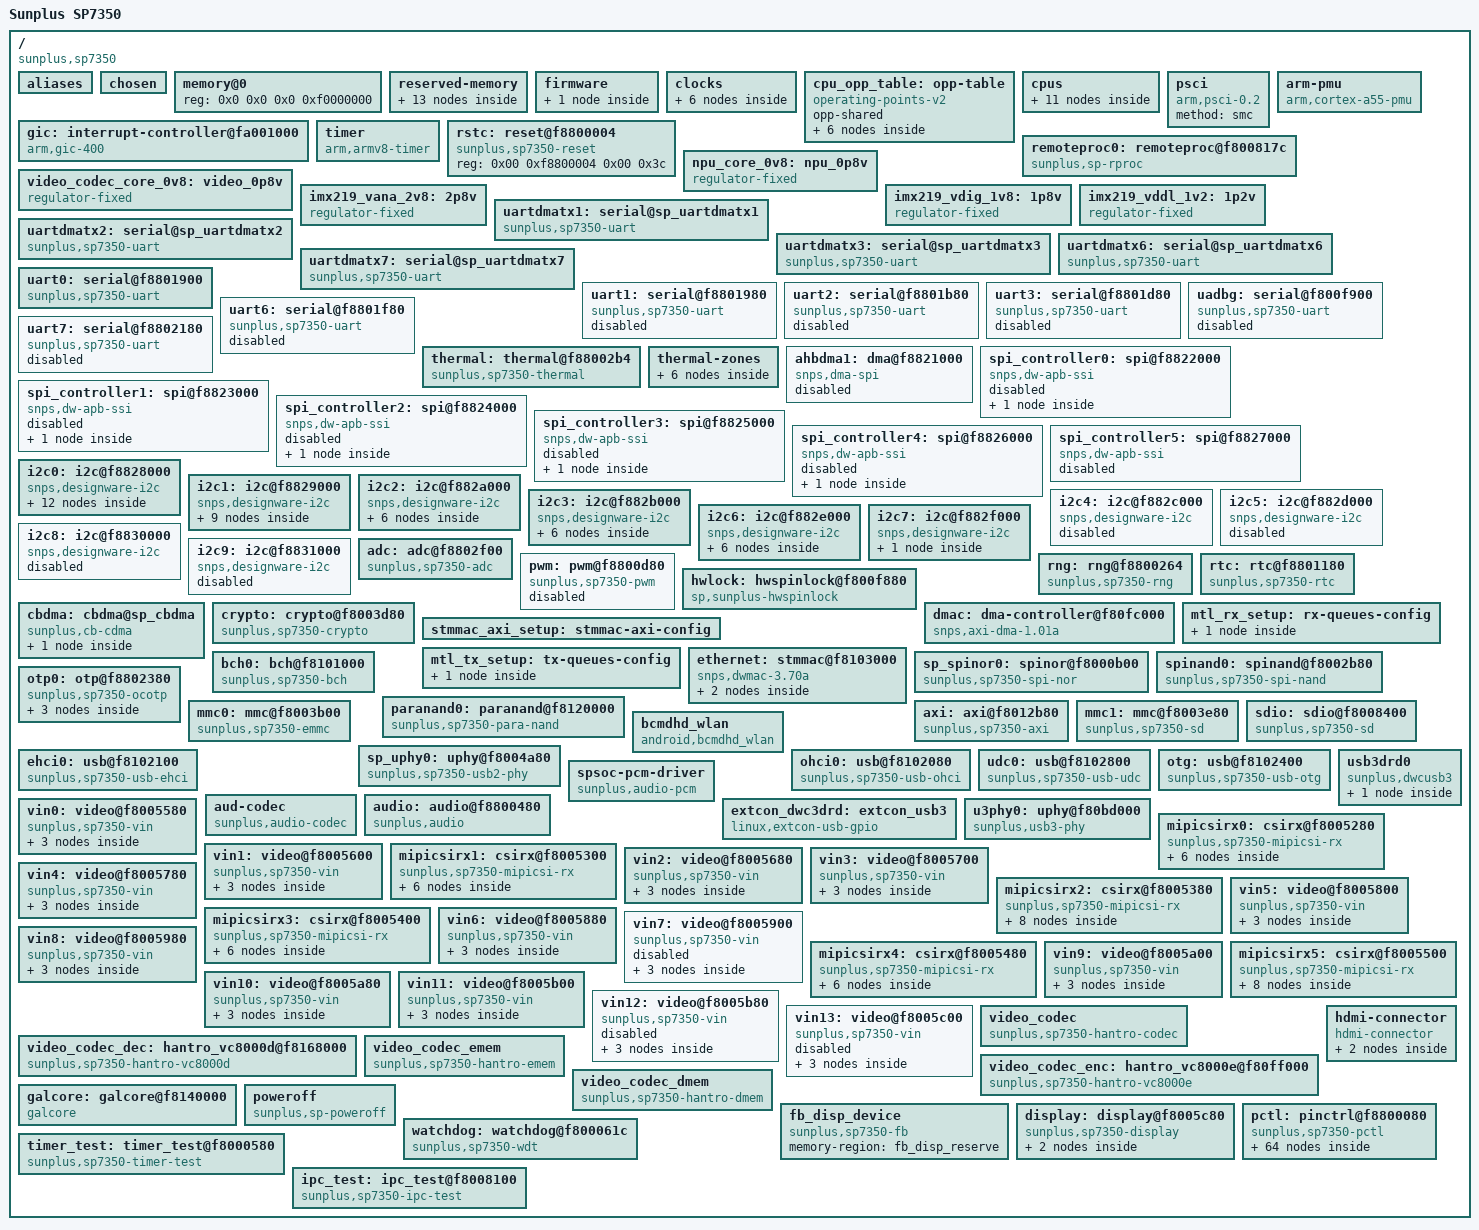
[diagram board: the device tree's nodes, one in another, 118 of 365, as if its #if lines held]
// SPDX-License-Identifier: (GPL-2.0 OR MIT)
/* Copyright (c) 2018-2019 Sunplus */

/dts-v1/;

#define CONFIG_SOC_SP7350

#include <dt-bindings/interrupt-controller/irq.h>
#include <dt-bindings/interrupt-controller/arm-gic.h>
#include <dt-bindings/gpio/gpio.h>
#include <dt-bindings/clock/sp-sp7350.h>
#include <dt-bindings/reset/sp-sp7350.h>
#include <dt-bindings/pinctrl/sppctl-sp7350.h>

//#define ENABLE_DMATX1
//#define ENABLE_DMATX2
//#define ENABLE_DMATX3
//#define ENABLE_DMATX6
//#define ENABLE_DMATX7

//#define MIPI_CSI_4VC
//#define IMX219_IN0
//#define IMX219_IN1
//#define IMX219_IN2
//#define IMX219_IN3
//#define IMX219_IN4
//#define IMX219_IN5
//#define TP2815_IN0
//#define TP2815_IN0_1LANE
//#define TP2815_IN0_2VC
//#define TP2815_IN1
//#define TP2815_IN1_1LANE
//#define TP2815_IN1_2VC
//#define TP2815_IN2
//#define TP2815_IN2_1LANE
//#define TP2815_IN2_2LANES
//#define TP2815_IN2_2VC
//#define TP2815_IN4
//#define TP2815_IN4_1LANE
//#define TP2815_IN4_2VC
//#define TP2815_IN5
//#define TP2815_IN5_1LANE
//#define TP2815_IN5_2LANES
//#define TP2815_IN5_2VC
//#define TP2815_IN5_4VC

//#define AP6256_WIFI
//#define AP6256_BT

//#define DISP_MIPITX_CSI
//#define DISP_MIPITX_CSI_480P
//#define DISP_MIPITX_CSI_720P
//#define DISP_MIPITX_CSI_1080P
//#define DISP_MIPITX_CSI_3840

//#define DISP_MIPITX_DSI_PANEL_240X320

//#define DISP_MIPITX_DSI_PANEL_480X1280
//#define DISP_MIPITX_DSI_VPP_SRC_480P
//#define DISP_MIPITX_DSI_VPP_SRC_720P
//#define DISP_MIPITX_DSI_VPP_SRC_1080P
//#define DISP_MIPITX_DSI_VPP_SRC_3840

#define LT8912B_HDMI_ENABLE
//#define LT8912B_HDMI_480P
//#define LT8912B_HDMI_720P
#define LT8912B_HDMI_1080P

/ {
	model = "Sunplus SP7350";
	compatible = "sunplus,sp7350";
	interrupt-parent = <&gic>;
	#address-cells = <2>;
	#size-cells = <2>;

	aliases {
#ifdef ENABLE_DMATX1
		serial21 = &uartdmatx1;
#endif
#ifdef ENABLE_DMATX2
		serial22 = &uartdmatx2;
#endif
#ifdef ENABLE_DMATX3
		serial23 = &uartdmatx3;
#endif
#ifdef ENABLE_DMATX6
		serial26 = &uartdmatx6;
#endif
#ifdef ENABLE_DMATX7
		serial27 = &uartdmatx7;
#endif
		serial0 = &uart0;
		serial1 = &uart1;
		serial2 = &uart2;
		serial3 = &uart3;
		serial5 = &uadbg;
		serial6 = &uart6;
		serial7 = &uart7;

		spim0 = &spi_controller0;
		spim1 = &spi_controller1;
		spim2 = &spi_controller2;
		spim3 = &spi_controller3;
		spim4 = &spi_controller4;
		spis5 = &spi_controller5;

		spi0 = &sp_spinor0;

		usb-device0 = &udc0;
	};

	chosen {
		bootargs = "console=ttyS0,115200 earlycon loglevel=8 no_console_suspend ";
		stdout-path = "serial0:115200n8";
	};

	memory@0 {
		device_type = "memory";
		reg = <0x0 0x0        0x0 0xf0000000>;
	};

	reserved-memory {
		#address-cells = <2>;
		#size-cells = <2>;
		ranges;

		/* TF-A reserve memory: 0x200000-0x2fffff, total 1M */
		tfa_reserve@200000 {
			reg = <0x0 0x200000 0x0 0x100000>;
			no-map;
		};

		/*OP-TEE reserve memory: 0x300000-0x4fffff, total 2M */
		optee_reserve@300000 {
			reg = <0x0 0x300000 0x0 0x200000>;
			no-map;
		};

		/* warmboot reserve memory: 0x100000-0x200000, total 1M, load firmware in rproc */
		rproc_0_reserved: rproc0@100000 {
			compatible = "shared-dma-pool";
			reg = <0x0 0x100000 0x0 0x100000>;
			no-map;
		};

		/* mipi-csi rx reserve memory: 0x4f600000~0x5bdfffff, total 200M */
		mipicsirx_reserve: mipicsirx@4f600000 {
			compatible = "shared-dma-pool";
			reg = <0x0 0x4f600000 0x0 0x0c800000>;
			no-map;
		};

		/* remoteproc reserve memory: 0x5be00000-0x5befffff, total 1M */
		vdev0buffer: vdev0buffer@5be00000 {
			compatible = "shared-dma-pool";
			reg = <0x0 0x5be00000 0x0 0x100000>;
			no-map;
		};
		vdev0vring0: vdev0vring0@5bf00000 {
			compatible = "shared-dma-pool";
			reg = <0x0 0x5bf00000 0x0 0x4000>;
			no-map;
		};
		vdev0vring1: vdev0vring1@5bf04000 {
			compatible = "shared-dma-pool";
			reg = <0x0 0x5bf04000 0x0 0x4000>;
			no-map;
		};
		vdev0_reserve: vdev0_reserve@5bf08000 {
			compatible = "shared-dma-pool";
			reg = <0x0 0x5bf08000 0x0 0xf8000>;
			no-map;
		};

		/* display fb reserve memory: 0x5c000000 ~ 0x5fffffff, total 64M */
		fb_disp_reserve: fb@5c000000 {
			compatible = "shared-dma-pool";
			reg = <0x0 0x5c000000 0x0 0x4000000>;
			no-map;
		};

		/* video encoder reserve memory: 0x60000000~0x73ffffff, total 320M */
		video_codec_encode: vcodec@60000000 {
			reg = <0x0 0x60000000 0x0 0x14000000>;
			no-map;
		};

		/* video decoder reserve memory: 0x74000000~0x77ffffff, total 64M */
		video_codec_decode: vcodec@74000000 {
			reg = <0x0 0x74000000 0x0 0x04000000>;
			no-map;
		};

		/* NPU reserve memory: 0x780000000 ~ 0x7fffffff, total 128M */
		npu_reserve: npu_reserve@78000000 {
			reg = <0x0 0x78000000 0x0 0x8000000>;
			no-map;
		};

		/* CM4 reserve memory: 0xfa240000 ~ 0xfa29ffff, total 384K */
		rproc0runaddr: cm4runaddr@fa240000 {
			compatible = "shared-dma-pool";
			reg = <0x0 0xfa240000 0x0 0x60000>;
			no-map;
		};
	};

	firmware {
		optee {
			compatible = "linaro,optee-tz";
			method = "smc";
		};
	};

	clocks {
		#address-cells = <2>;
		#size-cells = <2>;
		ranges;

		extclk: osc0 {
			compatible = "fixed-clock";
			#clock-cells = <0>;
			clock-frequency = <XTAL>;
			clock-output-names = "extclk";
		};

		rtcclk: rtcclk {
			compatible = "fixed-clock";
			#clock-cells = <0>;
			clock-frequency = <32000>;
			clock-output-names = "f_32k";
		};

		mipiclk: mipiclk {
			compatible = "fixed-clock";
			#clock-cells = <0>;
			clock-frequency = <320000000>;
			clock-output-names = "f_320m";
		};

		clkc: clkc@f8800104 {
			compatible = "sunplus,sp7350-clkc";
			reg = <0x00 0xf8800104 0x00 0x1fc>,  // MOON G2.1~G6
			      <0x00 0xf8000f00 0x00 0x080>;  // G30 QCTL
			#clock-cells = <1>;
		};

		imx219_clk: camera-imx219-clk {
			compatible = "fixed-clock";
			#clock-cells = <0>;
			clock-frequency = <24000000>;
		};

		tp2815_clk: camera-tp2815-clk {
			compatible = "fixed-clock";
			#clock-cells = <0>;
			clock-frequency = <27000000>;
		};
	};

	cpu_opp_table: opp-table {
		compatible = "operating-points-v2";
		opp-shared;

		opp-5 {
			opp-hz = /bits/ 64 <500000000>;
			opp-microvolt = <670000>;
		};

		opp-10 {
			opp-hz = /bits/ 64 <1000000000>;
			opp-microvolt = <700000>;
		};

		opp-15 {
			opp-hz = /bits/ 64 <1500000000>;
			opp-microvolt = <750000>;
		};

		opp-16 {
			opp-hz = /bits/ 64 <1600000000>;
			opp-microvolt = <770000>;
		};

		opp-17 {
			opp-hz = /bits/ 64 <1700000000>;
			opp-microvolt = <800000>;
		};

		opp-18 {
			opp-hz = /bits/ 64 <1800000000>;
			opp-microvolt = <840000>;
		};

		/*opp-19 {
			opp-hz = /bits/ 64 <1900000000>;
			opp-microvolt = <1000000>;
		};

		opp-20 {
			opp-hz = /bits/ 64 <2000000000>;
			opp-microvolt = <1000000>;
		};

		opp-21 {
			opp-hz = /bits/ 64 <2100000000>;
			opp-microvolt = <1000000>;
		};*/
	};

	cpus {
		#address-cells = <1>;
		#size-cells = <0>;

		cpu0: cpu@0 {
			device_type = "cpu";
			compatible = "arm,cortex-a55";
			reg = <0x0000>;
			enable-method = "psci";
			clocks = <&clkc PLLC>, <&clkc PLLL3>;
			clock-names = "PLLC", "PLLL3";
			proc-supply = <&rt5759_vproc_reg>;
			operating-points-v2 = <&cpu_opp_table>;
			next-level-cache = <&L2_0>;
			cpu-idle-states = <&CPU_SLEEP>;
		};

		cpu1: cpu@1 {
			device_type = "cpu";
			compatible = "arm,cortex-a55";
			reg = <0x0100>;
			enable-method = "psci";
			clocks = <&clkc PLLC>, <&clkc PLLL3>;
			clock-names = "PLLC", "PLLL3";
			proc-supply = <&rt5759_vproc_reg>;
			operating-points-v2 = <&cpu_opp_table>;
			next-level-cache = <&L2_1>;
			cpu-idle-states = <&CPU_SLEEP>;
		};

		cpu2: cpu@2 {
			device_type = "cpu";
			compatible = "arm,cortex-a55";
			reg = <0x0200>;
			enable-method = "psci";
			clocks = <&clkc PLLC>, <&clkc PLLL3>;
			clock-names = "PLLC", "PLLL3";
			proc-supply = <&rt5759_vproc_reg>;
			operating-points-v2 = <&cpu_opp_table>;
			next-level-cache = <&L2_2>;
			cpu-idle-states = <&CPU_SLEEP>;
		};

		cpu3: cpu@3 {
			device_type = "cpu";
			compatible = "arm,cortex-a55";
			reg = <0x0300>;
			enable-method = "psci";
			clocks = <&clkc PLLC>, <&clkc PLLL3>;
			clock-names = "PLLC", "PLLL3";
			proc-supply = <&rt5759_vproc_reg>;
			operating-points-v2 = <&cpu_opp_table>;
			next-level-cache = <&L2_3>;
			cpu-idle-states = <&CPU_SLEEP>;
		};

		idle-states {
			entry-method = "psci";

			CPU_SLEEP: cpu-sleep {
				compatible = "arm,idle-state";
				local-timer-stop;
				arm,psci-suspend-param = <0x0000000>;
				entry-latency-us = <120>;
				exit-latency-us = <250>;
				min-residency-us = <900>;
			};
		};

		L2_0: l2-cache-0 {
			compatible = "cache";
			cache-level = <2>;
			next-level-cache = <&L3>;
		};

		L2_1: l2-cache-1 {
			compatible = "cache";
			cache-level = <2>;
			next-level-cache = <&L3>;
		};

		L2_2: l2-cache-2 {
			compatible = "cache";
			cache-level = <2>;
			next-level-cache = <&L3>;
		};

		L2_3: l2-cache-3 {
			compatible = "cache";
			cache-level = <2>;
			next-level-cache = <&L3>;
		};

		L3: l3-cache {
			compatible = "cache";
			cache-level = <3>;
		};
	};

	psci {
		compatible = "arm,psci-0.2";
		method = "smc";
	};

	arm-pmu {
		compatible = "arm,cortex-a55-pmu", "arm,armv8-pmuv3";
		interrupts = <GIC_SPI 475 IRQ_TYPE_LEVEL_HIGH>,
			     <GIC_SPI 476 IRQ_TYPE_LEVEL_HIGH>,
			     <GIC_SPI 477 IRQ_TYPE_LEVEL_HIGH>,
			     <GIC_SPI 478 IRQ_TYPE_LEVEL_HIGH>;
		interrupt-affinity = <&cpu0>, <&cpu1>, <&cpu2>, <&cpu3>;
	};

	gic: interrupt-controller@fa001000 {
		compatible = "arm,gic-400";
		#interrupt-cells = <3>;
		interrupt-controller;
		reg = <0x00 0xfa001000 0x00 0x1000>,
		      <0x00 0xfa002000 0x00 0x2000>,
		      <0x00 0xfa004000 0x00 0x2000>,
		      <0x00 0xfa006000 0x00 0x2000>;
	};

	timer {
		compatible = "arm,armv8-timer";
		interrupt-parent = <&gic>;
		clock-frequency = <XTAL>;
		interrupts = <GIC_PPI 13 (GIC_CPU_MASK_RAW(15) | IRQ_TYPE_LEVEL_LOW)>,
			     <GIC_PPI 14 (GIC_CPU_MASK_RAW(15) | IRQ_TYPE_LEVEL_LOW)>,
			     <GIC_PPI 11 (GIC_CPU_MASK_RAW(15) | IRQ_TYPE_LEVEL_LOW)>,
			     <GIC_PPI 10 (GIC_CPU_MASK_RAW(15) | IRQ_TYPE_LEVEL_LOW)>;
	};

	rstc: reset@f8800004 {
		compatible = "sunplus,sp7350-reset";
		#reset-cells = <1>;
		reg = <0x00 0xf8800004 0x00 0x3c>;
		reg-names = "reset";
	};

	remoteproc0: remoteproc@f800817c {
		compatible = "sunplus,sp-rproc";
		firmware = "firmware";
		reg = <0 0xf800817c 0 4>, /* mbox G258.31, cpu0 to cpu2 direct reg07 */
		      <0 0xf8800250 0 4>,
		      <0 0xf80081fc 0 4>; /* mbox G259.31, cpu2 to cpu0 direct reg07 */
		interrupt-parent = <&gic>;
		interrupts = <GIC_SPI 125 IRQ_TYPE_LEVEL_HIGH>; /* CPU2_TO_0_DIRECT_INT7 */
		resets = <&rstc RST_CM4>;
		memory-region = <&rproc_0_reserved>, <&rproc0runaddr>,<&vdev0buffer>, <&vdev0vring0>, <&vdev0vring1>;
	};

	npu_core_0v8: npu_0p8v {
		compatible = "regulator-fixed";
		regulator-name = "npu_core";
		regulator-min-microvolt = <800000>;
		regulator-max-microvolt = <800000>;
		gpio = <&pctl 65 GPIO_ACTIVE_HIGH>;
		enable-active-high;
	};

	video_codec_core_0v8: video_0p8v {
		compatible = "regulator-fixed";
		regulator-name = "video_codec_core";
		regulator-min-microvolt = <800000>;
		regulator-max-microvolt = <800000>;
		gpio = <&pctl 66 GPIO_ACTIVE_HIGH>;
		enable-active-high;
	};

	imx219_vana_2v8: 2p8v {
		compatible = "regulator-fixed";
		regulator-name = "camera_vana";
		regulator-min-microvolt = <2800000>;
		regulator-max-microvolt = <2800000>;
		regulator-always-on;
	};

	imx219_vdig_1v8: 1p8v {
		compatible = "regulator-fixed";
		regulator-name = "camera_vdig";
		regulator-min-microvolt = <1500000>;
		regulator-max-microvolt = <1500000>;
		regulator-always-on;
	};

	imx219_vddl_1v2: 1p2v {
		compatible = "regulator-fixed";
		regulator-name = "camera_vddl";
		regulator-min-microvolt = <1200000>;
		regulator-max-microvolt = <1200000>;
		regulator-always-on;
	};

#ifdef ENABLE_DMATX1
	uartdmatx1: serial@sp_uartdmatx1 {
		compatible = "sunplus,sp7350-uart";
		reg = <0x00 0xf8801b40 0x00 0x40>, <0x00 0xf8801a80 0x00 0x80>;
		//clocks = <&clkc GDMAUA>;
		which-uart = <1>;
	};
#endif

#ifdef ENABLE_DMATX2
	uartdmatx2: serial@sp_uartdmatx2 {
		compatible = "sunplus,sp7350-uart";
		reg = <0x00 0xf8801d40 0x00 0x40>, <0x00 0xf8801c80 0x00 0x80>;
		//clocks = <&clkc GDMAUA>;
		which-uart = <2>;
	};
#endif

#ifdef ENABLE_DMATX3
	uartdmatx3: serial@sp_uartdmatx3 {
		compatible = "sunplus,sp7350-uart";
		reg = <0x00 0xf8801f40 0x00 0x40>, <0x00 0xf8801e80 0x00 0x80>;
		//clocks = <&clkc GDMAUA>;
		which-uart = <3>;
	};
#endif

#ifdef ENABLE_DMATX6
	uartdmatx6: serial@sp_uartdmatx6 {
		compatible = "sunplus,sp7350-uart";
		reg = <0x00 0xf8802140 0x00 0x40>, <0x00 0xf8802080 0x00 0x80>;
		//clocks = <&clkc GDMAUA>;
		which-uart = <6>;
	};
#endif

#ifdef ENABLE_DMATX7
	uartdmatx7: serial@sp_uartdmatx7 {
		compatible = "sunplus,sp7350-uart";
		reg = <0x00 0xf8802340 0x00 0x40>, <0x00 0xf8802280 0x00 0x80>;
		//clocks = <&clkc GDMAUA>;
		which-uart = <7>;
	};
#endif

	uart0: serial@f8801900 {
		compatible = "sunplus,sp7350-uart";
		reg = <0x00 0xf8801900 0x00 0x80>;
		interrupt-parent = <&gic>;
		interrupts = <GIC_SPI 60 IRQ_TYPE_LEVEL_HIGH>;
		clocks = <&clkc UA0>;
		resets = <&rstc RST_UA0>;
		pinctrl-names = "default";
		pinctrl-0 = <&uart0_pins>;
	};

	uart1: serial@f8801980 {
		compatible = "sunplus,sp7350-uart";
		reg = <0x00 0xf8801980 0x00 0x80>;
		interrupt-parent = <&gic>;
		interrupts = <GIC_SPI 61 IRQ_TYPE_LEVEL_HIGH>;
		clocks = <&clkc UA1>;
		resets = <&rstc RST_UA1>;
		pinctrl-names = "default";
		pinctrl-0 = <&uart1_pins &uart1_fc_pins>;
#ifndef AP6256_WIFI
	#ifndef AP6256_BT
		status = "disabled";
	#endif
#endif
	};

	uart2: serial@f8801b80 {
		compatible = "sunplus,sp7350-uart";
		reg = <0x00 0xf8801b80 0x00 0x80>;
		interrupt-parent = <&gic>;
		interrupts = <GIC_SPI 157 IRQ_TYPE_LEVEL_HIGH>;
		clocks = <&clkc UA2>;
		resets = <&rstc RST_UA2>;
		pinctrl-names = "default";
		pinctrl-0 = <&uart2_pins &uart2_fc_pins>;
		status = "disabled";
	};

	uart3: serial@f8801d80 {
		compatible = "sunplus,sp7350-uart";
		reg = <0x00 0xf8801d80 0x00 0x80>;
		interrupt-parent = <&gic>;
		interrupts = <GIC_SPI 158 IRQ_TYPE_LEVEL_HIGH>;
		clocks = <&clkc UA3>;
		resets = <&rstc RST_UA3>;
		pinctrl-names = "default";
		pinctrl-0 = <&uart3_pins>;
		status = "disabled";
	};

	uadbg: serial@f800f900 {
		compatible = "sunplus,sp7350-uart";
		reg = <0x00 0xf800f900 0x00 0x80>;
		interrupt-parent = <&gic>;
		interrupts = <GIC_SPI 35 IRQ_TYPE_LEVEL_HIGH>;
		clocks = <&clkc UADBG>;
		resets = <&rstc RST_UADBG>;
		pinctrl-names = "default";
		pinctrl-0 = <&uadbg_pins>;
		status = "disabled";
	};

	uart6: serial@f8801f80 {
		compatible = "sunplus,sp7350-uart";
		reg = <0x00 0xf8801f80 0x00 0x80>;
		interrupt-parent = <&gic>;
		interrupts = <GIC_SPI 162 IRQ_TYPE_LEVEL_HIGH>;
		clocks = <&clkc UA6>;
		resets = <&rstc RST_UA6>;
		pinctrl-names = "default";
		pinctrl-0 = <&uart6_pins>;
		status = "disabled";
	};

	uart7: serial@f8802180 {
		compatible = "sunplus,sp7350-uart";
		reg = <0x00 0xf8802180 0x00 0x80>;
		interrupt-parent = <&gic>;
		interrupts = <GIC_SPI 159 IRQ_TYPE_LEVEL_HIGH>;
		clocks = <&clkc UA7>;
		resets = <&rstc RST_UA7>;
		pinctrl-names = "default";
		pinctrl-0 = <&uart7_pins>;
		status = "disabled";
	};

	thermal: thermal@f88002b4 {
		compatible = "sunplus,sp7350-thermal";
		reg =<0x0 0xf88002b4 0x0 0x18>;
		clocks = <&clkc THERMAL>;
		resets = <&rstc RST_THERMAL>;
		#thermal-sensor-cells = <0>;
		nvmem-cell-names = "therm_calib";
		nvmem-cells = <&therm_calib>;
		//status = "disabled";
	};

	thermal-zones {
		cpu_thermal_zone: cpu-thermal {
			polling-delay-passive = <5000>;
			polling-delay = <1000>;

			thermal-sensors = <&thermal 0>;
			sustainable-power = <100000>;

			passive = <80>;
			trips {
					cpu_hott: cpu-hott {
						temperature = <120000>;
						hysteresis  = <1000>;
						type = "hot";
					};
					cpu_crit: cpu-crit {
						temperature = <125000>;
						hysteresis  = <0>;
						type = "critical";
					};
					cpu_trip0: cpu0 {
						temperature = <70000>;
						hysteresis = <2000>;
						type = "passive";
					};
					cpu_trip1: cpu1 {
						temperature = <80000>;
						hysteresis = <2000>;
						type = "active";
				};
			};
		};
	};

	// poweroff {
		//compatible = "system-shutdown";
	// };

	ahbdma1: dma@f8821000 {
		compatible = "snps,dma-spi";
		reg =<0x0 0xf8821000 0x0 0x400>;
		interrupt-parent = <&gic>;
		interrupts = <GIC_SPI 178 IRQ_TYPE_EDGE_RISING>,
			     <GIC_SPI 180 IRQ_TYPE_EDGE_RISING>,
			     <GIC_SPI 192 IRQ_TYPE_EDGE_RISING>,
			     <GIC_SPI 193 IRQ_TYPE_EDGE_RISING>,
			     <GIC_SPI 194 IRQ_TYPE_EDGE_RISING>,
			     <GIC_SPI 195 IRQ_TYPE_EDGE_RISING>,
			     <GIC_SPI 196 IRQ_TYPE_EDGE_RISING>,
			     <GIC_SPI 199 IRQ_TYPE_EDGE_RISING>;
		dma-channels = <8>;
		#dma-cells = <3>;
		dma-requests = <16>;
		chan_allocation_order = <1>;
		chan_priority = <1>;
		block_size = <0xfff>;
		dma-masters = <4>;
		data-width = <2 2 2 2>;
		multi-block = <0 0 0 0 0 0 0 0>;
		snps,max-burst-len = <128 128 128 128 128 128 128 128>;
		status = "disabled";
	};

	spi_controller0: spi@f8822000 {
		compatible = "snps,dw-apb-ssi";
		reg =<0x0 0xf8822000 0x0 0x100>;
		#address-cells = <1>;
		#size-cells = <0>;
		interrupt-parent = <&gic>;
		interrupts = <GIC_SPI 27 IRQ_TYPE_LEVEL_HIGH>;
		clocks = <&clkc SPICB0>;
		resets = <&rstc RST_SPICB0>;
		pinctrl-names = "default";
		pinctrl-0 = <&spi_master0_pins>;
		dmas = <&ahbdma1 0 0 0>,
		       <&ahbdma1 1 0 0>;
		dma-names = "rx", "tx";
		status = "disabled";
		spi@0 {
			compatible = "rohm,dh2228fv";
			spi-max-frequency = <5000000>;
			reg = <0x0>;
			status = "disabled";
		};
	};

	spi_controller1: spi@f8823000 {
		compatible = "snps,dw-apb-ssi";
		reg =<0x0 0xf8823000 0x0 0x100>;
		#address-cells = <1>;
		#size-cells = <0>;
		interrupt-parent = <&gic>;
		interrupts = <GIC_SPI 28 IRQ_TYPE_LEVEL_HIGH>;
		clocks = <&clkc SPICB1>;
		resets = <&rstc RST_SPICB1>;
		pinctrl-names = "default";
		pinctrl-0 = <&spi_master1_pins>;
		dmas = <&ahbdma1 2 0 0>,
		       <&ahbdma1 3 0 0>;
		dma-names = "rx", "tx";
		status = "disabled";
		spi@0 {
			compatible = "rohm,dh2228fv";
			spi-max-frequency = <5000000>;
			reg = <0x0>;
			status = "disabled";
		};
	};

	spi_controller2: spi@f8824000 {
		compatible = "snps,dw-apb-ssi";
		reg =<0x0 0xf8824000 0x0 0x100>;
		#address-cells = <1>;
		#size-cells = <0>;
		interrupt-parent = <&gic>;
		interrupts = <GIC_SPI 29 IRQ_TYPE_LEVEL_HIGH>;
		clocks = <&clkc SPICB2>;
		resets = <&rstc RST_SPICB2>;
		pinctrl-names = "default";
		pinctrl-0 = <&spi_master2_pins>;
		dmas = <&ahbdma1 4 0 0>,
		       <&ahbdma1 5 0 0>;
		dma-names = "rx", "tx";
		status = "disabled";
		spi@0 {
			compatible = "rohm,dh2228fv";
			spi-max-frequency = <5000000>;
			reg = <0x0>;
			status = "disabled";
		};
	};

	spi_controller3: spi@f8825000 {
		compatible = "snps,dw-apb-ssi";
		reg =<0x0 0xf8825000 0x0 0x100>;
		#address-cells = <1>;
		#size-cells = <0>;
		interrupt-parent = <&gic>;
		interrupts = <GIC_SPI 30 IRQ_TYPE_LEVEL_HIGH>;
		clocks = <&clkc SPICB3>;
		resets = <&rstc RST_SPICB3>;
		pinctrl-names = "default";
		pinctrl-0 = <&spi_master3_pins>;
		dmas = <&ahbdma1 6 0 0>,
		       <&ahbdma1 7 0 0>;
		dma-names = "rx", "tx";
		status = "disabled";
		spi@0 {
			compatible = "rohm,dh2228fv";
			spi-max-frequency = <5000000>;
			reg = <0x0>;
			status = "disabled";
		};
	};

	spi_controller4: spi@f8826000 {
		compatible = "snps,dw-apb-ssi";
		reg =<0x0 0xf8826000 0x0 0x100>;
		#address-cells = <1>;
		#size-cells = <0>;
		interrupt-parent = <&gic>;
		interrupts = <GIC_SPI 31 IRQ_TYPE_LEVEL_HIGH>;
		clocks = <&clkc SPICB4>;
		resets = <&rstc RST_SPICB4>;
		pinctrl-names = "default";
		pinctrl-0 = <&spi_master4_pins>;
		dmas = <&ahbdma1 6 0 0>,
		       <&ahbdma1 7 0 0>;
		dma-names = "rx", "tx";
		status = "disabled";
		spi@0 {
			compatible = "rohm,dh2228fv";
			spi-max-frequency = <5000000>;
			reg = <0x0>;
			status = "disabled";
		};
	};

	spi_controller5: spi@f8827000 {
		compatible = "snps,dw-apb-ssi";
		reg =<0x0 0xf8827000 0x0 0x100>;
		#address-cells = <1>;
		#size-cells = <0>;
		interrupt-parent = <&gic>;
		interrupts = <GIC_SPI 32 IRQ_TYPE_LEVEL_HIGH>;
		clocks = <&clkc SPICB5>;
		resets = <&rstc RST_SPICB5>;
		pinctrl-names = "default";
		pinctrl-0 = <&spi_slave0_pins>;
		status = "disabled";
	};

	i2c0: i2c@f8828000 {
		compatible = "snps,designware-i2c";
		reg =<0x0 0xf8828000 0x0 0x100>;
		interrupt-parent = <&gic>;
		interrupts = <GIC_SPI 8 IRQ_TYPE_LEVEL_HIGH>;
		clocks = <&clkc I2CM0>;
		resets = <&rstc RST_I2CM0>;
		i2c-sda-hold-time-ns = <1000>;
		//i2c-sda-falling-time-ns = <1>;
		//i2c-scl-falling-time-ns = <1>;
		//clock-frequency = <3400000>;
		clock-frequency = <400000>;
		pinctrl-names = "default";
		pinctrl-0 = <&i2c_combo0_pins>;
#if defined(IMX219_IN0) || defined(IMX219_IN2) || defined(TP2815_IN0) || defined(TP2815_IN2)
		status = "okay";
#else
		status = "disabled";
#endif

#if 0
		#address-cells = <1>;
		#size-cells = <0>;
		slave@50 {
			compatible = "linux,slave-24c02";
			reg = <0x40000050>;
		};
#endif
#ifdef IMX219_IN0 /* Add imx219 subnode in i2c0 */
		#address-cells = <1>;
		#size-cells = <0>;

		camera_0: sensor@10 {
			compatible = "sony,imx219";
			reg = <0x10>;
			clocks = <&imx219_clk>;
			VANA-supply = <&imx219_vana_2v8>;
			VDIG-supply = <&imx219_vdig_1v8>;
			VDDL-supply = <&imx219_vddl_1v2>;
			//pinctrl-names = "default";
			//pinctrl-0 = <&camera_0_pins>;
			//power-gpios = <&pctl 71 GPIO_ACTIVE_HIGH>;
			//reset-gpios = <&pctl 72 GPIO_ACTIVE_HIGH>;

			port {
				imx219_0: endpoint {
					remote-endpoint = <&csi2_0>;
					data-lanes = <1 2>;
					clock-noncontinuous;
					link-frequencies = /bits/ 64 <456000000>;
				};
			};
		};
#endif
#ifdef IMX219_IN2 /* Add imx219 subnode in i2c0 */
		#address-cells = <1>;
		#size-cells = <0>;

		camera_2: sensor@10 {
			compatible = "sony,imx219";
			reg = <0x10>;
			clocks = <&imx219_clk>;
			VANA-supply = <&imx219_vana_2v8>;
			VDIG-supply = <&imx219_vdig_1v8>;
			VDDL-supply = <&imx219_vddl_1v2>;
			//pinctrl-names = "default";
			//pinctrl-0 = <&camera_0_pins>;
			//power-gpios = <&pctl 71 GPIO_ACTIVE_HIGH>;
			//reset-gpios = <&pctl 72 GPIO_ACTIVE_HIGH>;

			port {
				imx219_2: endpoint {
					remote-endpoint = <&csi2_2>;
					data-lanes = <1 2>;
					clock-noncontinuous;
					link-frequencies = /bits/ 64 <456000000>;
				};
			};
		};
#endif
#ifdef TP2815_IN0 /* Add tp2815 subnode in i2c0 */
		#address-cells = <1>;
		#size-cells = <0>;

		camera_0: sensor@44 {
			compatible = "Techpoint,tp2815";
			reg = <0x44>;
			clocks = <&tp2815_clk>;
	#ifdef TP2815_IN0_2VC
			input-channel = <2>;
	#else
			input-channel = <1>;
	#endif
			input-standard = <0>;
			//pinctrl-names = "default";
			//pinctrl-0 = <&camera_0_pins>;
			//power-gpios = <&pctl 71 GPIO_ACTIVE_HIGH>;
			//reset-gpios = <&pctl 72 GPIO_ACTIVE_HIGH>;

			port {
				tp2815_0: endpoint {
					remote-endpoint = <&csi2_0>;
	#ifdef TP2815_IN0_1LANE
					data-lanes = <1>;
	#else
					data-lanes = <1 2>;
	#endif
					clock-continuous;
					link-frequencies = /bits/ 64 <456000000>;
				};
			};
		};
#endif
#ifdef TP2815_IN2 /* Add tp2815 subnode in i2c0 */
		#address-cells = <1>;
		#size-cells = <0>;

		camera_2: sensor@44 {
			compatible = "Techpoint,tp2815";
			reg = <0x44>;
			clocks = <&tp2815_clk>;
	#ifdef TP2815_IN2_2VC
			input-channel = <2>;
	#else
			input-channel = <1>;
	#endif
			input-standard = <0>;
			//pinctrl-names = "default";
			//pinctrl-0 = <&camera_0_pins>;
			//power-gpios = <&pctl 71 GPIO_ACTIVE_HIGH>;
			//reset-gpios = <&pctl 72 GPIO_ACTIVE_HIGH>;

			port {
				tp2815_2: endpoint {
					remote-endpoint = <&csi2_2>;
	#ifdef TP2815_IN2_1LANE
					data-lanes = <1>;
	#elif defined(TP2815_IN2_2LANES)
					data-lanes = <1 2>;
	#else
					data-lanes = <1 2 3 4>;
	#endif

					clock-continuous;
					link-frequencies = /bits/ 64 <456000000>;
				};
			};
		};
#endif
	};

	i2c1: i2c@f8829000 {
		compatible = "snps,designware-i2c";
		reg =<0x0 0xf8829000 0x0 0x100>;
		interrupt-parent = <&gic>;
		interrupts = <GIC_SPI 94 IRQ_TYPE_LEVEL_HIGH>;
		clocks = <&clkc I2CM1>;
		resets = <&rstc RST_I2CM1>;
		i2c-sda-hold-time-ns = <1000>;
		//i2c-sda-falling-time-ns = <1>;
		//i2c-scl-falling-time-ns = <1>;
		//clock-frequency = <3400000>;
		clock-frequency = <400000>;
		pinctrl-names = "default";
		pinctrl-0 = <&i2c_combo1_pins>;
#if defined(IMX219_IN1) || defined(IMX219_IN3) || defined(TP2815_IN1)
		status = "okay";
#else
		status = "disabled";
#endif

#ifdef IMX219_IN1 /* Add imx219 subnode in i2c1 */
		#address-cells = <1>;
		#size-cells = <0>;

		camera_1: sensor@10 {
			compatible = "sony,imx219";
			reg = <0x10>;
			clocks = <&imx219_clk>;
			VANA-supply = <&imx219_vana_2v8>;
			VDIG-supply = <&imx219_vdig_1v8>;
			VDDL-supply = <&imx219_vddl_1v2>;
			//pinctrl-names = "default";
			//pinctrl-0 = <&camera_1_pins>;
			//power-gpios = <&pctl 73 GPIO_ACTIVE_HIGH>;
			//reset-gpios = <&pctl 74 GPIO_ACTIVE_HIGH>;

			port {
				imx219_1: endpoint {
					remote-endpoint = <&csi2_1>;
					data-lanes = <1 2>;
					clock-noncontinuous;
					link-frequencies = /bits/ 64 <456000000>;
				};
			};
		};
#endif
#ifdef IMX219_IN3 /* Add imx219 subnode in i2c1 */
		#address-cells = <1>;
		#size-cells = <0>;

		camera_3: sensor@10 {
			compatible = "sony,imx219";
			reg = <0x10>;
			clocks = <&imx219_clk>;
			VANA-supply = <&imx219_vana_2v8>;
			VDIG-supply = <&imx219_vdig_1v8>;
			VDDL-supply = <&imx219_vddl_1v2>;
			//pinctrl-names = "default";
			//pinctrl-0 = <&camera_1_pins>;
			//power-gpios = <&pctl 73 GPIO_ACTIVE_HIGH>;
			//reset-gpios = <&pctl 74 GPIO_ACTIVE_HIGH>;

			port {
				imx219_3: endpoint {
					remote-endpoint = <&csi2_3>;
					data-lanes = <1 2>;
					clock-noncontinuous;
					link-frequencies = /bits/ 64 <456000000>;
				};
			};
		};
#endif
#ifdef TP2815_IN1 /* Add tp2815 subnode in i2c1 */
		#address-cells = <1>;
		#size-cells = <0>;

		camera_1: sensor@44 {
			compatible = "Techpoint,tp2815";
			reg = <0x44>;
			clocks = <&tp2815_clk>;
	#ifdef TP2815_IN1_2VC
			input-channel = <2>;
	#else
			input-channel = <1>;
	#endif
			input-standard = <0>;
			//pinctrl-names = "default";
			//pinctrl-0 = <&camera_1_pins>;
			//power-gpios = <&pctl 73 GPIO_ACTIVE_HIGH>;
			//reset-gpios = <&pctl 74 GPIO_ACTIVE_HIGH>;

			port {
				tp2815_1: endpoint {
					remote-endpoint = <&csi2_1>;
	#ifdef TP2815_IN1_1LANE
					data-lanes = <1>;
	#else
					data-lanes = <1 2>;
	#endif
					clock-continuous;
					link-frequencies = /bits/ 64 <456000000>;
				};
			};
		};
#endif
	};

	i2c2: i2c@f882a000 {
		compatible = "snps,designware-i2c";
		reg =<0x0 0xf882a000 0x0 0x100>;
		interrupt-parent = <&gic>;
		interrupts = <GIC_SPI 95 IRQ_TYPE_LEVEL_HIGH>;
		clocks = <&clkc I2CM2>;
		resets = <&rstc RST_I2CM2>;
		i2c-sda-hold-time-ns = <1000>;
		clock-frequency = <400000>;
		pinctrl-names = "default";
		pinctrl-0 = <&i2c_combo2_pins>;
#if defined(IMX219_IN4) || defined(TP2815_IN4)
		status = "okay";
#else
		status = "disabled";
#endif

#ifdef IMX219_IN4 /* Add imx219 subnode in i2c2 */
		#address-cells = <1>;
		#size-cells = <0>;

		camera_4: sensor@10 {
			compatible = "sony,imx219";
			reg = <0x10>;
			clocks = <&imx219_clk>;
			VANA-supply = <&imx219_vana_2v8>;
			VDIG-supply = <&imx219_vdig_1v8>;
			VDDL-supply = <&imx219_vddl_1v2>;
			//pinctrl-names = "default";
			//pinctrl-0 = <&camera_4_pins>;
			//power-gpios = <&pctl 79 GPIO_ACTIVE_HIGH>;
			//reset-gpios = <&pctl 80 GPIO_ACTIVE_HIGH>;

			port {
				imx219_4: endpoint {
					remote-endpoint = <&csi2_4>;
					data-lanes = <1 2>;
					clock-noncontinuous;
					link-frequencies = /bits/ 64 <456000000>;
				};
			};
		};
#endif
#ifdef TP2815_IN4 /* Add tp2815 subnode in i2c2 */
		#address-cells = <1>;
		#size-cells = <0>;

		camera_4: sensor@44 {
			compatible = "Techpoint,tp2815";
			reg = <0x44>;
			clocks = <&tp2815_clk>;
	#ifdef TP2815_IN4_2VC
			input-channel = <2>;
	#else
			input-channel = <1>;
	#endif
			input-standard = <0>;
			//pinctrl-names = "default";
			//pinctrl-0 = <&camera_4_pins>;
			//power-gpios = <&pctl 79 GPIO_ACTIVE_HIGH>;
			//reset-gpios = <&pctl 80 GPIO_ACTIVE_HIGH>;

			port {
				tp2815_4: endpoint {
					remote-endpoint = <&csi2_4>;
	#ifdef TP2815_IN4_1LANE
					data-lanes = <1>;
	#else
					data-lanes = <1 2>;
	#endif
					clock-continuous;
					link-frequencies = /bits/ 64 <456000000>;
				};
			};
		};
#endif
	};

	i2c3: i2c@f882b000 {
		compatible = "snps,designware-i2c";
		reg =<0x0 0xf882b000 0x0 0x100>;
		interrupt-parent = <&gic>;
		interrupts = <GIC_SPI 96 IRQ_TYPE_LEVEL_HIGH>;
		clocks = <&clkc I2CM3>;
		resets = <&rstc RST_I2CM3>;
		i2c-sda-hold-time-ns = <1000>;
		clock-frequency = <400000>;
		pinctrl-names = "default";
		pinctrl-0 = <&i2c_combo3_pins>;
#if defined(IMX219_IN5) || defined(TP2815_IN5)
		status = "okay";
#else
		status = "disabled";
#endif

#ifdef IMX219_IN5 /* Add imx219 subnode in i2c3 */
		#address-cells = <1>;
		#size-cells = <0>;

		camera_5: sensor@10 {
			compatible = "sony,imx219";
			reg = <0x10>;
			clocks = <&imx219_clk>;
			VANA-supply = <&imx219_vana_2v8>;
			VDIG-supply = <&imx219_vdig_1v8>;
			VDDL-supply = <&imx219_vddl_1v2>;
			//pinctrl-names = "default";
			//pinctrl-0 = <&camera_5_pins>;
			//power-gpios = <&pctl 81 GPIO_ACTIVE_HIGH>;
			//reset-gpios = <&pctl 82 GPIO_ACTIVE_HIGH>;

			port {
				imx219_5: endpoint {
					remote-endpoint = <&csi2_5>;
					data-lanes = <1 2>;
					clock-noncontinuous;
					link-frequencies = /bits/ 64 <456000000>;
				};
			};
		};
#endif
#ifdef TP2815_IN5 /* Add tp2815 subnode in i2c3 */
		#address-cells = <1>;
		#size-cells = <0>;

		camera_5: sensor@44 {
			compatible = "Techpoint,tp2815";
			reg = <0x44>;
			clocks = <&tp2815_clk>;
	#ifdef TP2815_IN5_4VC
			input-channel = <4>;
	#elif defined(TP2815_IN5_2VC)
			input-channel = <2>;
	#else
			input-channel = <1>;
	#endif
			input-standard = <0>;
			//pinctrl-names = "default";
			//pinctrl-0 = <&camera_5_pins>;
			//power-gpios = <&pctl 81 GPIO_ACTIVE_HIGH>;
			//reset-gpios = <&pctl 82 GPIO_ACTIVE_HIGH>;

			port {
				tp2815_5: endpoint {
					remote-endpoint = <&csi2_5>;
	#ifdef TP2815_IN5_2LANES
					data-lanes = <1 2>;
	#else
					data-lanes = <1 2 3 4>;
	#endif
					clock-continuous;
					link-frequencies = /bits/ 64 <456000000>;
				};
			};
		};
#endif
	};

	i2c4: i2c@f882c000 {
		compatible = "snps,designware-i2c";
		reg =<0x0 0xf882c000 0x0 0x100>;
		interrupt-parent = <&gic>;
		interrupts = <GIC_SPI 97 IRQ_TYPE_LEVEL_HIGH>;
		clocks = <&clkc I2CM4>;
		resets = <&rstc RST_I2CM4>;
		i2c-sda-hold-time-ns = <1000>;
		clock-frequency = <400000>;
		pinctrl-names = "default";
		pinctrl-0 = <&i2c_combo4_pins>;
		status = "disabled";
	};

	i2c5: i2c@f882d000 {
		compatible = "snps,designware-i2c";
		reg =<0x0 0xf882d000 0x0 0x100>;
		interrupt-parent = <&gic>;
		interrupts = <GIC_SPI 98 IRQ_TYPE_LEVEL_HIGH>;
		clocks = <&clkc I2CM5>;
		resets = <&rstc RST_I2CM5>;
		i2c-sda-hold-time-ns = <1000>;
		clock-frequency = <400000>;
		pinctrl-names = "default";
		pinctrl-0 = <&i2c_combo5_pins>;
		status = "disabled";
	};

	i2c6: i2c@f882e000 {
		compatible = "snps,designware-i2c";
		reg =<0x0 0xf882e000 0x0 0x100>;
		interrupt-parent = <&gic>;
		interrupts = <GIC_SPI 22 IRQ_TYPE_LEVEL_HIGH>;
		clocks = <&clkc I2CM6>;
		resets = <&rstc RST_I2CM6>;
		i2c-sda-hold-time-ns = <2000>;
#ifdef LT8912B_HDMI_ENABLE /* Add lt8912b subnode in i2c6 */
		clock-frequency = <100000>;
#else
		clock-frequency = <400000>;
#endif
		pinctrl-names = "default";
		pinctrl-0 = <&i2c_combo6_pins>;
		status = "okay";

#ifdef LT8912B_HDMI_ENABLE /* Add lt8912b subnode in i2c6 */
		#address-cells = <1>;
		#size-cells = <0>;

		lontium_lt8912b: hdmi@48 {
			compatible = "lontium,lt8912b";
			reg = <0x48>;
			//reset-gpios = <&pctl 74 GPIO_ACTIVE_LOW>;
			#if defined(LT8912B_HDMI_480P)
			hdmi-timing = <0x0>;
			#elif defined(LT8912B_HDMI_720P)
			hdmi-timing = <0x2>;
			#elif defined(LT8912B_HDMI_1080P)
			hdmi-timing = <0x3>;
			#else
			hdmi-timing = <0x2>;
			#endif
			/*
			 * 0x0: 720x480
			 * 0x2: 1280x720
			 * 0x3: 1920x1080
			 */
			status = "okay";
			ports {
				#address-cells = <1>;
				#size-cells = <0>;
				port@0 {
					reg = <0>;
					lt8912b_in: endpoint {
						remote-endpoint = <&disp_phy>;
						data-lanes = <1 2 3 4>;
					};
				};

				port@1 {
					reg = <1>;
					lt8912b_out: endpoint {
						remote-endpoint = <&hdmi_con_out>;
					};
				};
			};
		};
#endif
	};

	i2c7: i2c@f882f000 {
		compatible = "snps,designware-i2c";
		reg =<0x0 0xf882f000 0x0 0x100>;
		interrupt-parent = <&gic>;
		interrupts = <GIC_SPI 110 IRQ_TYPE_LEVEL_HIGH>;
		clocks = <&clkc I2CM7>;
		resets = <&rstc RST_I2CM7>;
		i2c-sda-hold-time-ns = <1000>;
		clock-frequency = <400000>;
		pinctrl-names = "default";
		pinctrl-0 = <&i2c_combo7_pins>;
		//status = "disabled";

		#address-cells = <1>;
		#size-cells = <0>;
		rt5759_vproc_reg: regulator@62 {
			compatible = "richtek,rt5759";
			reg = <0x62>;
			regulator-name = "rt5759-buck";
			regulator-min-microvolt = <630000>;
			regulator-max-microvolt = <1100000>;
			regulator-allowed-modes = <0 1>;	// 0: auto mode (PSKIP), 1: force pwm mode
			regulator-initial-mode = <1>;
			regulator-always-on;
		};
	};

	i2c8: i2c@f8830000 {
		compatible = "snps,designware-i2c";
		reg =<0x0 0xf8830000 0x0 0x100>;
		interrupt-parent = <&gic>;
		interrupts = <GIC_SPI 111 IRQ_TYPE_LEVEL_HIGH>;
		clocks = <&clkc I2CM8>;
		resets = <&rstc RST_I2CM8>;
		i2c-sda-hold-time-ns = <1000>;
		clock-frequency = <400000>;
		pinctrl-names = "default";
		pinctrl-0 = <&i2c_combo8_pins>;
		status = "disabled";
	};

	i2c9: i2c@f8831000 {
		compatible = "snps,designware-i2c";
		reg =<0x0 0xf8831000 0x0 0x100>;
		interrupt-parent = <&gic>;
		interrupts = <GIC_SPI 169 IRQ_TYPE_LEVEL_HIGH>;
		clocks = <&clkc I2CM9>;
		resets = <&rstc RST_I2CM9>;
		i2c-sda-hold-time-ns = <1000>;
		clock-frequency = <400000>;
		pinctrl-names = "default";
		pinctrl-0 = <&i2c_combo9_pins>;
		status = "disabled";
	};

	adc: adc@f8802f00 {
		compatible = "sunplus,sp7350-adc";
		reg = <0x0 0xf8802f00 0x0 0x80>;
		hwlocks = <&hwlock 1>;
		//status = "disabled";
	};

	pwm: pwm@f8800d80 {
		#pwm-cells = <2>;
		compatible = "sunplus,sp7350-pwm";
		reg = <0x0 0xf8800d80 0x0 0x100>;
		clocks = <&clkc DISP_PWM>;
		resets = <&rstc RST_DISP_PWM>;
		pinctrl-names = "default";
		pinctrl-0 = <&pwm0_pins &pwm1_pins &pwm2_pins &pwm3_pins>;
		status = "disabled";
	};

	rng: rng@f8800264 {
		compatible = "sunplus,sp7350-rng";
		reg = <0x0 0xf8800264 0x0 0x08>;
		clocks = <&clkc PRNG>;
		resets = <&rstc RST_PRNG>;
	};

	rtc: rtc@f8801180 {
		compatible = "sunplus,sp7350-rtc";
		reg = <0x0 0xf8801180 0x0 0x30>,
			  <0x0 0xf8008178 0x0 0x04>; /* mbox G258.30, cpu0 to cpu2 direct reg06 */
		reg-names = "rtc_reg","mbox_reg";
		clocks = <&clkc RTC>;
		resets = <&rstc RST_RTC>;
		interrupt-parent = <&gic>;
		interrupts = <GIC_SPI 141 IRQ_TYPE_EDGE_RISING>;
	};

	hwlock: hwspinlock@f800f880 {
		compatible = "sp,sunplus-hwspinlock";
		#hwlock-cells = <1>;
		reg = <0 0xf800f880 0 0x80>;
		clocks = <&clkc SEMAPHORE>;
		clock-names = "hsem";
	};

	cbdma: cbdma@sp_cbdma {
		compatible = "sunplus,cb-cdma";
		reg = <0x0 0xf8000d00 0x0 0x80>;
		reg-names = "cb_dma";
		clocks = <&clkc CBDMA0>;
		resets = <&rstc RST_CBDMA0>;
		interrupt-parent = <&gic>;
		interrupts = <GIC_SPI 74 IRQ_TYPE_LEVEL_HIGH>;
		addrwidth = <0x20>;
		dma-channel-0 {
			compatible = "sunplus,cb-cdma-channel";
			interrupts = <GIC_SPI 74 IRQ_TYPE_LEVEL_HIGH>;
			datawidth = <0x20>;
		};
	};

	crypto: crypto@f8003d80 {
		compatible = "sunplus,sp7350-crypto";
		reg = <0x0 0xf8003d80 0x0 0x100>; /* G123 ~ G124 */
		clocks = <&clkc SEC>;
		resets = <&rstc RST_SEC>;
		interrupt-parent = <&gic>;
		interrupts = <GIC_SPI 48 IRQ_TYPE_LEVEL_HIGH>;
	};

	dmac: dma-controller@f80fc000 {
		compatible = "snps,axi-dma-1.01a";
		reg = <0x00 0xf80fc000 0x00 0x10a0>;
		clocks = <&clkc AXI_DMA>;
		clock-names = "core-clk";
		resets = <&rstc RST_AXI_DMA>;
		reset-names = "core-rstc";
		interrupt-parent = <&gic>;
		interrupts = <GIC_SPI 20 IRQ_TYPE_LEVEL_HIGH>;
		#dma-cells = <1>;
		dma-channels = <16>;
		snps,dma-masters = <2>;
		snps,data-width = <4>;
		snps,block-size = <4096 4096 4096 4096 4096 4096 4096 4096
				   4096 4096 4096 4096 4096 4096 4096 4096>;
		snps,priority = <0 1 2 3 4 5 6 7 8 9 10 11 12 13 14 15>;
		snps,axi-max-burst-len = <16>;
	};

	stmmac_axi_setup: stmmac-axi-config {
		/*LPI switch*/
		snps,lpi_en;
		snps,xit_frm;
		snps,wr_osr_lmt = <0xf>;
		snps,rd_osr_lmt = <0xf>;
		snps,blen = <256 128 64 32 0 0 0>;
		//snps,axi_fb;
		snps,axi_mb;
	};

	mtl_rx_setup: rx-queues-config {
		snps,rx-queues-to-use = <1>;
		snps,rx-sched-sp;
		//snps,rx-sched-wsp;
		queue0 {
			snps,dcb-algorithm;
			//snps,avb-algorithm;
			snps,map-to-dma-channel = <0x0>;
			snps,priority = <0x0>;
		};
	};

	mtl_tx_setup: tx-queues-config {
		snps,tx-queues-to-use = <1>;
		/*use will cause dev_watchdog() function panic*/
		//snps,tx-sched-wrr;
		//snps,tx-sched-wfq;
		//snps,tx-sched-dwrr;
		snps,tx-sched-sp;
		queue0 {
			/*use will cause dev_watchdog() function panic*/
			//snps,weight = <0x10>;
			snps,dcb-algorithm;
			snps,map-to-dma-channel = <0x0>;
			snps,priority = <0x0>;
		};
		/*use will cause dev_watchdog() function panic*/
		//queue1 {
		//	snps,avb-algorithm;
		//	snps,send_slope = <0x1000>;
		//	snps,idle_slope = <0x2000>;
		//	snps,high_credit = <0x3e800>;
		//	snps,low_credit = <0xffc18000>;
		//	snps,priority = <0x2>;
		//};
	};

	ethernet: stmmac@f8103000 {
		compatible = "snps,dwmac-3.70a";
		reg = <0x00 0xf8103000 0x00 0x2000>;
		interrupt-parent = <&gic>;
		interrupts = <GIC_SPI 19 IRQ_TYPE_LEVEL_HIGH>,
			     <GIC_SPI 21 IRQ_TYPE_LEVEL_HIGH>,
			     <GIC_SPI 58 IRQ_TYPE_LEVEL_HIGH>;
		interrupt-names = "macirq", "eth_wake_irq", "eth_lpi";
		clocks = <&clkc GMAC>;
		clock-names = "stmmaceth";
		clock_in_out = "output";
		clock-frequency = <125000000>;
		resets = <&rstc RST_GMAC>, <&rstc RST_PD_GMAC>;
		reset-names = "rstc_gmac", "rstc_pd_gmac";
		pinctrl-names = "default";
		pinctrl-0 = <&gmac_pins>;
		mac-mode = "rgmii";
		/* Reset time is 20ms, 100ms for rtl8211f */
		snps,reset-delays-us = <0 30000 150000>;
		/* fixed-burst-->speed little high*/
		snps,mixed-burst;
		//snps,fixed-burst;
		/* default threshold=64, real use 128 */
		//snps,force_thresh_dma_mode;
		/* default */
		snps,force_sf_dma_mode;
		/*LPI switch*/
		snps,en-tx-lpi-clockgating;
		snps,multicast-filter-bins = <256>;
		snps,perfect-filter-entries = <128>;
		snps,ps-speed = <1000>;
		//snps,pbl = <16>;
		//snps,txpbl = <16>;
		//snps,rxpbl = <16>;
		//snps,no-pbl-x8;
		//snps,tso;
		rx-fifo-depth = <16384>;
		tx-fifo-depth = <16384>;
		snps,axi-config = <&stmmac_axi_setup>;
		snps,mtl-rx-config = <&mtl_rx_setup>;
		snps,mtl-tx-config = <&mtl_tx_setup>;
		//max-speed = <1000>;
		nvmem-cell-names = "mac-address";
		nvmem-cells = <&mac_addr>;
		clk_csr = <4>;
		phy-mode = "rgmii";
		phy-handle = <&phy0>;
		/*id-->use phy hardway tx/rx delay 2ns, txid-->use phy hardway tx delay 2ns, rxid-->use phy hardway rx delay 2ns*/
		//phy-mode = "rgmii-id";
		//phy-mode = "rgmii-txid";
		//phy-mode = "rgmii-rxid";
		//tx_delay = <0x25>;
		//rx_delay = <0x15>;
		//status = "disabled";

		mdio0 {
			#address-cells = <1>;
			#size-cells = <0>;
			compatible = "snps,dwmac-mdio";
			phy0: ethernet-phy@0 {
				compatible = "ethernet-phy-id001c.c916", "ethernet-phy-ieee802.3-c22";
				//compatible = "ethernet-phy-id001c.c816", "ethernet-phy-ieee802.3-c22";
				reg = <1>;
				reset-assert-us = <1000>;
				reset-deassert-us = <2000>;
			};
		};
	};

	sp_spinor0: spinor@f8000b00 {
		compatible = "sunplus,sp7350-spi-nor";
		reg = <0x0 0xf8000b00 0x0 0x80>;
		interrupt-parent = <&gic>;
		interrupts = <GIC_SPI 18 IRQ_TYPE_LEVEL_HIGH>;
		clocks = <&clkc SPIFL>;
		resets = <&rstc RST_SPIFL>;
		pinctrl-names = "default";
		pinctrl-0 = <&spi_nor_pins>;
		spi-max-frequency = <45000000>;
		spi-chip-selection = <0>;
		read-timing-selection = <3>;
		write-timing-selection = <0>;
	};

	spinand0: spinand@f8002b80 {
		compatible = "sunplus,sp7350-spi-nand";
		reg = <0x0 0xf8002b80 0x0 0x60>;
		interrupt-parent = <&gic>;
		interrupts = <GIC_SPI 23 IRQ_TYPE_LEVEL_HIGH>;
		clocks = <&clkc SPIND>;
		resets = <&rstc RST_SPIND>;
		pinctrl-names = "default";
		pinctrl-0 = <&spi_nand_pins>;
		spi-max-frequency = <45000000>;
		read-timing-selection = <2>;
	};

	bch0: bch@f8101000 {
		compatible = "sunplus,sp7350-bch";
		reg = <0x0 0xf8101000 0x0 0x30>;
		interrupt-parent = <&gic>;
		interrupts = <GIC_SPI 24 IRQ_TYPE_LEVEL_HIGH>;
		clocks = <&clkc BCH>;
		resets = <&rstc RST_BCH>;
	};

	paranand0: paranand@f8120000 {
		compatible = "sunplus,sp7350-para-nand";
		reg = <0x0 0xf8120000 0x0 0x3000>, <0x0 0xfb000000 0x0 0x4000000>;
		interrupt-parent = <&gic>;
		interrupts = <GIC_SPI 71 IRQ_TYPE_LEVEL_HIGH>;
		clocks = <&clkc PNAND>;
		resets = <&rstc RST_PNAND>;
		clock-frequency = <400000000>;
		dmas = <&dmac 2>;
		dma-names = "rxtx";
		pinctrl-names = "default";
		pinctrl-0 = <&para_nand_pins>;
	};

	otp0: otp@f8802380 {
		compatible = "sunplus,sp7350-ocotp";
		reg = <0x00 0xf8802380 0x00 0x60>, <0x00 0xf8802400 0x00 0x80>, <0x00 0xf8802480 0x00 0x18>;
		reg-names = "hb_gpio", "otprx", "otp_key";
		clocks = <&clkc OTPRX>;
		resets = <&rstc RST_OTPRX>;
		#address-cells = <1>;
		#size-cells = <1>;
		therm_calib: therm_calib@9 {
			reg = <0x9 0x3>;
		};
		mac_addr: mac-address@16 {
			reg = <0x16 0x6>;
		};
		disc_vol: disc_vol@2d {
			reg = <0x2d 0x1>;
		};
	};

	mmc0: mmc@f8003b00 {
		compatible = "sunplus,sp7350-emmc";
		reg = <0x0 0xf8003b00 0x0 0x180>, <0x0 0xf8803280 0x0 0x80>, <0x0 0xf8803354 0x0 0x0C>;
		interrupt-parent = <&gic>;
		interrupts = <GIC_SPI 17 IRQ_TYPE_LEVEL_HIGH>;
		clocks = <&clkc CARD_CTL0>;
		resets = <&rstc RST_CARD_CTL0>;
		pinctrl-names = "default";
		pinctrl-0 = <&emmc_pins>;
		bus-width = <8>;
		max-frequency = <45000000>;
		non-removable;
		disable-wp;
		cap-mmc-highspeed;
		mmc-ddr-1_8v;
		#mmc-hs200-1_8v;
		no-sdio;
		no-sd;
	};

	axi: axi@f8012b80 {
		compatible = "sunplus,sp7350-axi";
		reg = <0x0 0xf8012b80 0x0 0x80>, <0x0 0xf8012c00 0x0 0x80>, <0x0 0xf8012c80 0x0 0x80>,
		      <0x0 0xf8012d00 0x0 0x80>, <0x0 0xf8012d80 0x0 0x80>, <0x0 0xf8012e00 0x0 0x80>,
		      <0x0 0xf8012e80 0x0 0x80>, <0x0 0xf8012f00 0x0 0x80>, <0x0 0xf8012f80 0x0 0x80>,
		      <0x0 0xf8013000 0x0 0x80>, <0x0 0xf8013080 0x0 0x80>, <0x0 0xf8013100 0x0 0x80>,
		      <0x0 0xf8013180 0x0 0x80>, <0x0 0xf8013200 0x0 0x80>, <0x0 0xf8013280 0x0 0x80>,
		      <0x0 0xf8013300 0x0 0x80>, <0x0 0xf8013380 0x0 0x80>, <0x0 0xf8013400 0x0 0x80>,
		      <0x0 0xf8013480 0x0 0x80>, <0x0 0xf8013500 0x0 0x80>, <0x0 0xf8013580 0x0 0x80>,
		      <0x0 0xf8013600 0x0 0x80>, <0x0 0xf8013680 0x0 0x80>, <0x0 0xf8013700 0x0 0x80>,
		      <0x0 0xf8013780 0x0 0x80>, <0x0 0xf8013800 0x0 0x80>, <0x0 0xf8013880 0x0 0x80>,
		      <0x0 0xf8013900 0x0 0x80>, <0x0 0xf8013980 0x0 0x80>, <0x0 0xf8013a00 0x0 0x80>,
			  <0x0 0xf8013a80 0x0 0x80>, <0x0 0xf8013b00 0x0 0x80>, <0x0 0xf8013b80 0x0 0x80>;
		reg-names = "axi_mon", "axi_0", "axi_1",
			    "axi_2", "axi_3", "axi_4",
			    "axi_5", "axi_6", "axi_7",
			    "axi_8", "axi_9", "axi_10",
			    "axi_11", "axi_12", "axi_13",
			    "axi_14", "axi_15", "axi_16",
			    "axi_17", "axi_18", "axi_19",
			    "axi_20", "axi_21", "axi_22",
			    "axi_23", "axi_24", "axi_25",
			    "axi_26", "axi_27", "axi_28",
				"axi_29", "axi_30", "axi_31";
		interrupt-parent = <&gic>;
		interrupts = <GIC_SPI 49 IRQ_TYPE_LEVEL_HIGH>;
	};

	mmc1: mmc@f8003e80 {
		compatible = "sunplus,sp7350-sd";
		reg = <0x0 0xf8003e80 0x0 0x180>;
		interrupt-parent = <&gic>;
		interrupts = <GIC_SPI 16 IRQ_TYPE_LEVEL_HIGH>;
		clocks = <&clkc CARD_CTL1>;
		resets = <&rstc RST_CARD_CTL1>;
		pinctrl-names = "default";
		pinctrl-0 = <&sdcard_pins>;
		cd-gpios = <&pctl 17 GPIO_ACTIVE_LOW>;
		delay-val = <0x777110>;
		bus-width = <4>;
		max-frequency = <160000000>;
		disable-wp;
		cap-sd-highspeed;
		sd-uhs-sdr12;
		sd-uhs-sdr25;
		sd-uhs-sdr50;
		sd-uhs-sdr104;
		sd-uhs-ddr50;
		no-sdio;
		no-mmc;
	};

	sdio: sdio@f8008400 {
		compatible = "sunplus,sp7350-sd";
		reg = < 0x0 0xf8008400 0x0 0x180>;
		interrupt-parent = <&gic>;
		interrupts = <GIC_SPI 15 IRQ_TYPE_LEVEL_HIGH>;
		clocks = <&clkc CARD_CTL2>;
		resets = <&rstc RST_CARD_CTL2>;
		pinctrl-names = "default";
		pinctrl-0 = <&sdio_pins>;
		delay-val = <0x777110>;
		bus-width = <4>;
		max-frequency = <160000000>;
		non-removable;
		disable-wp;
		cap-sd-highspeed;
		sd-uhs-sdr12;
		sd-uhs-sdr25;
		sd-uhs-sdr50;
		sd-uhs-sdr104;
		sd-uhs-ddr50;
		cap-sdio-irq;
		keep-power-in-suspend;
		no-sd;
		no-mmc;
		#address-cells = <1>;
		#size-cells = <0>;
		//status = "disabled";
	};

#ifdef AP6256_WIFI
	bcmdhd_wlan {
		compatible = "android,bcmdhd_wlan";
		pinctrl-names = "default";
		pinctrl-0 = <&gpio_int0_pins>;
		gpio_wl_reg_on = <&pctl 56 GPIO_ACTIVE_LOW>;
		interrupt-parent = <&gic>;
		interrupts = <GIC_SPI 0 IRQ_TYPE_LEVEL_HIGH>;
	};
#endif
	sp_uphy0: uphy@f8004a80 {
		compatible = "sunplus,sp7350-usb2-phy";
		clocks = <&clkc UPHY0>;
		resets = <&rstc RST_UPHY0>;
		reg = <0x0 0xf8004a80 0x0 0x80>, <0x0 0xf8800200 0x0 0x80>;
		reg-names = "phy", "moon4";
		interrupt-parent = <&gic>;
		interrupts = <GIC_SPI 148 IRQ_TYPE_LEVEL_HIGH>;
		nvmem-cell-names = "disc_vol";
		nvmem-cells = <&disc_vol>;
		#phy-cells = <0>;
		sunplus,disc-vol-addr-off = <0>;
		pinctrl-names = "default";
		pinctrl-0 = <&otg_pins>;
	};

	ehci0: usb@f8102100 {
		compatible = "sunplus,sp7350-usb-ehci";
		clocks = <&clkc USBC0>;
		resets = <&rstc RST_USBC0>;
		reg = <0x00 0xf8102100 0x00 0x68>;
		interrupt-parent = <&gic>;
		interrupts = <GIC_SPI 183 IRQ_TYPE_LEVEL_HIGH>;
		phys = <&sp_uphy0>;
		phy-names = "uphy";
	};

	ohci0: usb@f8102080 {
		compatible = "sunplus,sp7350-usb-ohci";
		clocks = <&clkc USBC0>;
		resets = <&rstc RST_USBC0>;
		reg = <0x00 0xf8102080 0x00 0x68>, <0x00 0xf8800000 0x00 0x80>;
		interrupt-parent = <&gic>;
		interrupts = <GIC_SPI 184 IRQ_TYPE_LEVEL_HIGH>;
		phys = <&sp_uphy0>;
		phy-names = "uphy";
	};

	udc0: usb@f8102800 {
		compatible = "sunplus,sp7350-usb-udc";
		clocks = <&clkc USBC0>;
		resets = <&rstc RST_USBC0>;
		reg = <0x0 0xf8102800 0x0 0x288>, <0x0 0xf8800200 0x0 0x80>, <0x0 0xf8800000 0x0 0x80>,
		      <0x0 0xf8800080 0x0 0x80>, <0x0 0xf8800100 0x0 0x80>, <0x0 0xf8004a80 0x0 0x80>,
		      <0x0 0xf8802380 0x0 0x80>;
		interrupt-parent = <&gic>;
		interrupts = <GIC_SPI 182 IRQ_TYPE_LEVEL_HIGH>;
		phys = <&sp_uphy0>;
		phy-names = "uphy";
	};

	otg: usb@f8102400 {
		compatible = "sunplus,sp7350-usb-otg";
		clocks = <&clkc USBC0>;
		resets = <&rstc RST_USBC0>;
		reg = <0x0 0xf8102400 0x0 0x80>;
		interrupt-parent = <&gic>;
		interrupts = <GIC_SPI 181 IRQ_TYPE_LEVEL_HIGH>;
		phys = <&sp_uphy0>;
		phy-names = "uphy";
	};

	spsoc-pcm-driver {
		compatible = "sunplus,audio-pcm";
		//status = "disabled";
	};

	aud-codec {
		compatible = "sunplus,audio-codec";
		//status = "disabled";
	};

	audio: audio@f8800480 {
		compatible = "sunplus,audio";
		reg = <0x00 0xf8800480 0x00 0x700>;
		reg-names = "audio";
		clocks = <&clkc AUD>, <&clkc PLLA>;
		clock-names = "aud", "pll_a";
		resets = <&rstc RST_AUD>;
		pinctrl-names = "default";
#ifdef AP6256_WIFI
		pinctrl-0 = <&aud_au_adc_data0_pins &aud_dac_xck_pins>, <&aud_adc2_data0_pins &aud_au2_ck_pins>;
#else
		pinctrl-0 = <&aud_au_adc_data0_pins &aud_dac_xck_pins>, <&aud_adc1_data0_pins &aud_au1_ck_pins>, <&aud_adc2_data0_pins &aud_au2_ck_pins>;
#endif
		//status = "disabled";
	};

	extcon_dwc3drd: extcon_usb3 {
		compatible = "linux,extcon-usb-gpio";
		pinctrl-names = "default";
		pinctrl-0 = <&dwc3id_pins>;
		id-gpio = <&pctl 99 GPIO_ACTIVE_HIGH>;
	};

	usb3drd0: usb3drd0{
		compatible = "sunplus,dwcusb3";
		#address-cells = <2>;
		#size-cells = <2>;
		ranges;
		clocks = <&clkc USB30C0>, <&clkc USB30C0>, <&clkc USB30C0>;
		clock-names = "ref","bus_early","suspend";
		resets = <&rstc RST_USB30C0>;

		usbdrd_dwc3_0: dwc3@f80a1000 {
			compatible = "synopsys,dwc3";
			reg = <0x0 0xf80a1000 0x0 0xe000>;
			interrupt-parent = <&gic>;
			interrupts = <GIC_SPI 179 IRQ_TYPE_LEVEL_HIGH>;
			maximum-speed = "super-speed";
			dr_mode = "otg";
			snps,dis_u2_susphy_quirk;
			phy_type = "utmi_wide";
			usb-role-switch;
			extcon = <&extcon_dwc3drd>;
			phys = <&u3phy0>, <&u3phy0>;
			phy-names = "usb3-phy", "usb2-phy";
		};
	};

	u3phy0: uphy@f80bd000 {
		compatible = "sunplus,usb3-phy";
		reg = <0x0 0xf80bd000 0x0 0x80>, <0x0 0xf80a1430 0x0 0x80>;
		interrupt-parent = <&gic>;
		interrupts = <GIC_SPI 191 IRQ_TYPE_LEVEL_HIGH>;
		clocks = <&clkc U3PHY0>, <&clkc USB30C0>;
		clock-names = "clkc_u3phy", "clkc_u3";
		resets = <&rstc RST_U3PHY0>;
		reset-names = "rstc_u3phy";
		pinctrl-names = "default";
		pinctrl-0 = <&typec_pins>;
		typec-gpios = <&pctl 98 GPIO_ACTIVE_HIGH>;
		#phy-cells = <0>;
	};

	mipicsirx0: csirx@f8005280 {
		compatible = "sunplus,sp7350-mipicsi-rx";
		reg = <0x0 0xf8005280 0x0 0x80>;
		reg-names = "mipicsi";
		clocks = <&clkc MIPICSI0>;
		clock-names = "clk_mipicsi";
		resets = <&rstc RST_MIPICSI0>;
		reset-names = "rstc_mipicsi";
		sunplus,id = <0>;
#if defined(IMX219_IN0) || defined(TP2815_IN0)
		status = "okay";
#else
		status = "disabled";
#endif

		/* Virtual channel related properties */
		max_channels = <4>;
#ifdef IMX219_IN0
		num_channels = <1>;
#elif defined(TP2815_IN0)
	#ifdef TP2815_IN0_2VC
		num_channels = <2>;
	#else
		num_channels = <1>;
	#endif
#else
		num_channels = <2>;
#endif

		ports {
			#address-cells = <1>;
			#size-cells = <0>;

			/* Input port node, sigle endpoint, connected to the CSI-2 transmitter */
#ifdef IMX219_IN0 /* Add imx219 subnode in i2c0 */
			port@0 {
				reg = <0>;

				/* MIPI CSI-2 bus endpoint */
				csi2_0: endpoint {
					remote-endpoint = <&imx219_0>;
					bus-type = <4>;
					clock-lanes = <0>;
					data-lanes = <1 2>;
				};
			};
#endif
#ifdef TP2815_IN0 /* Add tp2815 subnode in i2c0 */
			port@0 {
				reg = <0>;

				/* MIPI CSI-2 bus endpoint */
				csi2_0: endpoint {
					remote-endpoint = <&tp2815_0>;
					bus-type = <4>;
					clock-lanes = <0>;
	#ifdef TP2815_IN0_1LANE
					data-lanes = <1>;
	#else
					data-lanes = <1 2>;
	#endif
				};
			};
#endif

			/* Output port node, multiple endpoints, connected to VIN modules */
			port@1 {
				#address-cells = <1>;
				#size-cells = <0>;

				reg = <1>;

				csi0vin0: endpoint@0 {
					reg = <0>;
					remote-endpoint = <&vin0csi0>;
				};

				csi0vin1: endpoint@1 {
					reg = <1>;
					remote-endpoint = <&vin1csi0>;
				};
			};
		};
	};

	vin0: video@f8005580 {
		compatible = "sunplus,sp7350-vin";
		reg = <0x0 0xf8005580 0x0 0x80>;
		reg-names = "csiiw";
		interrupt-parent = <&gic>;
		interrupts = <GIC_SPI 36 IRQ_TYPE_LEVEL_HIGH>,
			     <GIC_SPI 37 IRQ_TYPE_LEVEL_HIGH>;
		interrupt-names = "fs_irq", "fe_irq";
		clocks = <&clkc VI0_CSIIW0>;
		clock-names = "clk_csiiw";
		resets = <&rstc RST_VI0_CSIIW0>;
		reset-names = "rstc_csiiw";
		memory-region = <&mipicsirx_reserve>;
		sunplus,id = <0>;
#if defined(IMX219_IN0) || defined(TP2815_IN0)
		status = "okay";
#else
		status = "disabled";
#endif

		ports {
			#address-cells = <1>;
			#size-cells = <0>;

			/* Input port node, default mode, connected to CSI-2 receivers */
			port@1 {
				#address-cells = <1>;
				#size-cells = <0>;

				reg = <1>;

				vin0csi0: endpoint@0 {
					reg = <0>;
					remote-endpoint = <&csi0vin0>;
				};
			};
		};
	};

	vin1: video@f8005600 {
		compatible = "sunplus,sp7350-vin";
		reg = <0x0 0xf8005600 0x0 0x80>;
		reg-names = "csiiw";
		interrupt-parent = <&gic>;
		interrupts = <GIC_SPI 38 IRQ_TYPE_LEVEL_HIGH>,
			     <GIC_SPI 39 IRQ_TYPE_LEVEL_HIGH>;
		interrupt-names = "fs_irq", "fe_irq";
		clocks = <&clkc VI0_CSIIW1>;
		clock-names = "clk_csiiw";
		resets = <&rstc RST_VI0_CSIIW1>;
		reset-names = "rstc_csiiw";
		memory-region = <&mipicsirx_reserve>;
		sunplus,id = <1>;
#if defined(TP2815_IN0) && defined(TP2815_IN0_2VC)
		status = "okay";
#else
		status = "disabled";
#endif

		ports {
			#address-cells = <1>;
			#size-cells = <0>;

			/* Input port node, default mode, connected to CSI-2 receivers */
			port@1 {
				#address-cells = <1>;
				#size-cells = <0>;

				reg = <1>;

				vin1csi0: endpoint@0 {
					reg = <0>;
					remote-endpoint = <&csi0vin1>;
				};
			};
		};
	};

	mipicsirx1: csirx@f8005300 {
		compatible = "sunplus,sp7350-mipicsi-rx";
		reg = <0x0 0xf8005300 0x0 0x80>;
		reg-names = "mipicsi";
		clocks = <&clkc MIPICSI1>;
		clock-names = "clk_mipicsi";
		resets = <&rstc RST_MIPICSI1>;
		reset-names = "rstc_mipicsi";
		sunplus,id = <1>;
#if defined(IMX219_IN1) || defined(TP2815_IN1)
		status = "okay";
#else
		status = "disabled";
#endif

		/* Virtual channel related properties */
		max_channels = <4>;
#ifdef IMX219_IN1
		num_channels = <1>;
#elif defined(TP2815_IN1)
	#ifdef TP2815_IN1_2VC
		num_channels = <2>;
	#else
		num_channels = <1>;
	#endif
#else
		num_channels = <2>;
#endif

		ports {
			#address-cells = <1>;
			#size-cells = <0>;

			/* Input port node, sigle endpoint, connected to the CSI-2 transmitter */
#ifdef IMX219_IN1 /* Add imx219 subnode in i2c1 */
			port@0 {
				reg = <0>;

				/* MIPI CSI-2 bus endpoint */
				csi2_1: endpoint {
					remote-endpoint = <&imx219_1>;
					bus-type = <4>;
					clock-lanes = <0>;
					data-lanes = <1 2>;
				};
			};
#endif
#ifdef TP2815_IN1 /* Add tp2815 subnode in i2c1 */
			port@0 {
				reg = <0>;

				/* MIPI CSI-2 bus endpoint */
				csi2_1: endpoint {
					remote-endpoint = <&tp2815_1>;
					bus-type = <4>;
					clock-lanes = <0>;
	#ifdef TP2815_IN1_1LANE
					data-lanes = <1>;
	#else
					data-lanes = <1 2>;
	#endif
				};
			};
#endif

			/* Output port node, multiple endpoints, connected to VIN modules */
			port@1 {
				#address-cells = <1>;
				#size-cells = <0>;

				reg = <1>;

				csi1vin2: endpoint@0 {
					reg = <0>;
					remote-endpoint = <&vin2csi1>;
				};

				csi1vin3: endpoint@1 {
					reg = <1>;
					remote-endpoint = <&vin3csi1>;
				};
			};
		};
	};

	vin2: video@f8005680 {
		compatible = "sunplus,sp7350-vin";
		reg = <0x0 0xf8005680 0x0 0x80>;
		reg-names = "csiiw";
		interrupt-parent = <&gic>;
		interrupts = <GIC_SPI 40 IRQ_TYPE_LEVEL_HIGH>,
			     <GIC_SPI 41 IRQ_TYPE_LEVEL_HIGH>;
		interrupt-names = "fs_irq", "fe_irq";
		clocks = <&clkc VI1_CSIIW0>;
		clock-names = "clk_csiiw";
		resets = <&rstc RST_VI1_CSIIW0>;
		reset-names = "rstc_csiiw";
		memory-region = <&mipicsirx_reserve>;
		sunplus,id = <2>;
#if defined(IMX219_IN1) || defined(TP2815_IN1)
		status = "okay";
#else
		status = "disabled";
#endif

		ports {
			#address-cells = <1>;
			#size-cells = <0>;

			/* Input port node, default mode, connected to CSI-2 receivers */
			port@1 {
				#address-cells = <1>;
				#size-cells = <0>;

				reg = <1>;

				vin2csi1: endpoint@1 {
					reg = <1>;
					remote-endpoint = <&csi1vin2>;
				};
			};
		};
	};

	vin3: video@f8005700 {
		compatible = "sunplus,sp7350-vin";
		reg = <0x0 0xf8005700 0x0 0x80>;
		reg-names = "csiiw";
		interrupt-parent = <&gic>;
		interrupts = <GIC_SPI 42 IRQ_TYPE_LEVEL_HIGH>,
			     <GIC_SPI 43 IRQ_TYPE_LEVEL_HIGH>;
		interrupt-names = "fs_irq", "fe_irq";
		clocks = <&clkc VI1_CSIIW1>;
		clock-names = "clk_csiiw";
		resets = <&rstc RST_VI1_CSIIW1>;
		reset-names = "rstc_csiiw";
		memory-region = <&mipicsirx_reserve>;
		sunplus,id = <3>;
#if defined(TP2815_IN1) && defined(TP2815_IN1_2VC)
		status = "okay";
#else
		status = "disabled";
#endif

		ports {
			#address-cells = <1>;
			#size-cells = <0>;

			/* Input port node, default mode, connected to CSI-2 receivers */
			port@1 {
				#address-cells = <1>;
				#size-cells = <0>;

				reg = <1>;

				vin3csi1: endpoint@1 {
					reg = <1>;
					remote-endpoint = <&csi1vin3>;
				};
			};
		};
	};

	mipicsirx2: csirx@f8005380 {
		compatible = "sunplus,sp7350-mipicsi-rx";
		reg = <0x0 0xf8005380 0x0 0x80>, <0x0 0xf8005200 0x0 0x80>;
		reg-names = "mipicsi", "mipicsi23sel";
		clocks = <&clkc MIPICSI2>;
		clock-names = "clk_mipicsi";
		resets = <&rstc RST_MIPICSI2>;
		reset-names = "rstc_mipicsi";
		sunplus,id = <2>;
#if defined(IMX219_IN2) || defined(TP2815_IN2)
		status = "okay";
#else
		status = "disabled";
#endif

		/* Virtual channel related properties */
		max_channels = <4>;
#ifdef MIPI_CSI_4VC
	#ifdef TP2815_IN2
		num_channels = <1>;
	#else
		num_channels = <4>;
	#endif
#else
	#ifdef IMX219_IN2
		num_channels = <1>;
	#elif defined(TP2815_IN2)
		#ifdef TP2815_IN2_2VC
		num_channels = <2>;
		#else
		num_channels = <1>;
		#endif
	#else
		num_channels = <2>;
	#endif
#endif

		ports {
			#address-cells = <1>;
			#size-cells = <0>;

			/* Input port node, sigle endpoint, connected to the CSI-2 transmitter */
#ifdef IMX219_IN2 /* Add imx219 subnode in i2c2 */
			port@0 {
				reg = <0>;

				/* MIPI CSI-2 bus endpoint */
				csi2_2: endpoint {
					remote-endpoint = <&imx219_2>;
					bus-type = <4>;
					clock-lanes = <0>;
					data-lanes = <1 2>;
				};
			};
#endif
#ifdef TP2815_IN2 /* Add tp2815 subnode in i2c2 */
			port@0 {
				reg = <0>;

				/* MIPI CSI-2 bus endpoint */
				csi2_2: endpoint {
					remote-endpoint = <&tp2815_2>;
					bus-type = <4>;
					clock-lanes = <0>;
	#ifdef TP2815_IN2_1LANE
					data-lanes = <1>;
	#elif defined(TP2815_IN2_2LANES)
					data-lanes = <1 2>;
	#else
					data-lanes = <1 2 3 4>;
	#endif
				};
			};
#endif

			/* Output port node, multiple endpoints, connected to VIN modules */
			port@1 {
				#address-cells = <1>;
				#size-cells = <0>;

				reg = <1>;

				csi2vin4: endpoint@0 {
					reg = <0>;
					remote-endpoint = <&vin4csi2>;
				};

				csi2vin5: endpoint@1 {
					reg = <1>;
					remote-endpoint = <&vin5csi2>;
				};

#ifdef MIPI_CSI_4VC
				csi2vin6: endpoint@2 {
					reg = <2>;
					remote-endpoint = <&vin6csi2>;
				};

				csi2vin7: endpoint@3 {
					reg = <3>;
					remote-endpoint = <&vin7csi2>;
				};
#endif
			};
		};
	};

	vin4: video@f8005780 {
		compatible = "sunplus,sp7350-vin";
		reg = <0x0 0xf8005780 0x0 0x80>;
		reg-names = "csiiw";
		interrupt-parent = <&gic>;
		interrupts = <GIC_SPI 80 IRQ_TYPE_LEVEL_HIGH>,
			     <GIC_SPI 81 IRQ_TYPE_LEVEL_HIGH>;
		interrupt-names = "fs_irq", "fe_irq";
		clocks = <&clkc VI23_CSIIW0>;
		clock-names = "clk_csiiw";
		resets = <&rstc RST_VI23_CSIIW0>;
		reset-names = "rstc_csiiw";
		memory-region = <&mipicsirx_reserve>;
		sunplus,id = <4>;
#if defined(IMX219_IN2) || defined(TP2815_IN2)
		status = "okay";
#else
		status = "disabled";
#endif

		ports {
			#address-cells = <1>;
			#size-cells = <0>;

			/* Input port node, default mode, connected to CSI-2 receivers */
			port@1 {
				#address-cells = <1>;
				#size-cells = <0>;

				reg = <1>;

				vin4csi2: endpoint@2 {
					reg = <2>;
					remote-endpoint = <&csi2vin4>;
				};
			};
		};
	};

	vin5: video@f8005800 {
		compatible = "sunplus,sp7350-vin";
		reg = <0x0 0xf8005800 0x0 0x80>;
		reg-names = "csiiw";
		interrupt-parent = <&gic>;
		interrupts = <GIC_SPI 82 IRQ_TYPE_LEVEL_HIGH>,
			     <GIC_SPI 83 IRQ_TYPE_LEVEL_HIGH>;
		interrupt-names = "fs_irq", "fe_irq";
		clocks = <&clkc VI23_CSIIW1>;
		clock-names = "clk_csiiw";
		resets = <&rstc RST_VI23_CSIIW1>;
		reset-names = "rstc_csiiw";
		memory-region = <&mipicsirx_reserve>;
		sunplus,id = <5>;
#if defined(TP2815_IN2) && defined(TP2815_IN2_2VC)
		status = "okay";
#else
		status = "disabled";
#endif

		ports {
			#address-cells = <1>;
			#size-cells = <0>;

			/* Input port node, default mode, connected to CSI-2 receivers */
			port@1 {
				#address-cells = <1>;
				#size-cells = <0>;

				reg = <1>;

				vin5csi2: endpoint@2 {
					reg = <2>;
					remote-endpoint = <&csi2vin5>;
				};
			};
		};
	};

#ifndef MIPI_CSI_4VC
	mipicsirx3: csirx@f8005400 {
		compatible = "sunplus,sp7350-mipicsi-rx";
		reg = <0x0 0xf8005400 0x0 0x80>, <0x0 0xf8005200 0x0 0x80>;
		reg-names = "mipicsi", "mipicsi23sel";
		clocks = <&clkc MIPICSI3>;
		clock-names = "clk_mipicsi";
		resets = <&rstc RST_MIPICSI3>;
		reset-names = "rstc_mipicsi";
		sunplus,id = <3>;
#if defined(IMX219_IN3)
		status = "okay";
#else
		status = "disabled";
#endif

		/* Virtual channel related properties */
		max_channels = <4>;
#ifdef IMX219_IN3
		num_channels = <1>;
#else
		num_channels = <2>;
#endif

		ports {
			#address-cells = <1>;
			#size-cells = <0>;

			/* Input port node, sigle endpoint, connected to the CSI-2 transmitter */
#ifdef IMX219_IN3 /* Add imx219 subnode in i2c3 */
			port@0 {
				reg = <0>;

				/* MIPI CSI-2 bus endpoint */
				csi2_3: endpoint {
					remote-endpoint = <&imx219_3>;
					bus-type = <4>;
					clock-lanes = <0>;
					data-lanes = <1 2>;
				};
			};
#endif

			/* Output port node, multiple endpoints, connected to VIN modules */
			port@1 {
				#address-cells = <1>;
				#size-cells = <0>;

				reg = <1>;

				csi3vin6: endpoint@0 {
					reg = <0>;
					remote-endpoint = <&vin6csi3>;
				};

				csi3vin7: endpoint@1 {
					reg = <1>;
					remote-endpoint = <&vin7csi3>;
				};
			};
		};
	};
#endif

	vin6: video@f8005880 {
		compatible = "sunplus,sp7350-vin";
		reg = <0x0 0xf8005880 0x0 0x80>;
		reg-names = "csiiw";
		interrupt-parent = <&gic>;
		interrupts = <GIC_SPI 84 IRQ_TYPE_LEVEL_HIGH>,
			     <GIC_SPI 85 IRQ_TYPE_LEVEL_HIGH>;
		interrupt-names = "fs_irq", "fe_irq";
		clocks = <&clkc VI23_CSIIW2>;
		clock-names = "clk_csiiw";
		resets = <&rstc RST_VI23_CSIIW2>;
		reset-names = "rstc_csiiw";
		memory-region = <&mipicsirx_reserve>;
		sunplus,id = <6>;
#if defined(IMX219_IN3)
		status = "okay";
#else
		status = "disabled";
#endif

		ports {
			#address-cells = <1>;
			#size-cells = <0>;

			/* Input port node, default mode, connected to CSI-2 receivers */
			port@1 {
				#address-cells = <1>;
				#size-cells = <0>;

				reg = <1>;

#ifdef MIPI_CSI_4VC
				vin6csi2: endpoint@2 {
					reg = <2>;
					remote-endpoint = <&csi2vin6>;
				};
#else
				vin6csi3: endpoint@3 {
					reg = <3>;
					remote-endpoint = <&csi3vin6>;
				};
#endif
			};
		};
	};

	vin7: video@f8005900 {
		compatible = "sunplus,sp7350-vin";
		reg = <0x0 0xf8005900 0x0 0x80>;
		reg-names = "csiiw";
		interrupt-parent = <&gic>;
		interrupts = <GIC_SPI 86 IRQ_TYPE_LEVEL_HIGH>,
			     <GIC_SPI 87 IRQ_TYPE_LEVEL_HIGH>;
		interrupt-names = "fs_irq", "fe_irq";
		clocks = <&clkc VI23_CSIIW3>;
		clock-names = "clk_csiiw";
		resets = <&rstc RST_VI23_CSIIW3>;
		reset-names = "rstc_csiiw";
		memory-region = <&mipicsirx_reserve>;
		sunplus,id = <7>;
		status = "disabled";

		ports {
			#address-cells = <1>;
			#size-cells = <0>;

			/* Input port node, default mode, connected to CSI-2 receivers */
			port@1 {
				#address-cells = <1>;
				#size-cells = <0>;

				reg = <1>;

#ifdef MIPI_CSI_4VC
				vin7csi2: endpoint@2 {
					reg = <2>;
					remote-endpoint = <&csi2vin7>;
				};
#else
				vin7csi3: endpoint@3 {
					reg = <3>;
					remote-endpoint = <&csi3vin7>;
				};
#endif
			};
		};
	};

	mipicsirx4: csirx@f8005480 {
		compatible = "sunplus,sp7350-mipicsi-rx";
		reg = <0x0 0xf8005480 0x0 0x80>;
		reg-names = "mipicsi";
		clocks = <&clkc MIPICSI4>;
		clock-names = "clk_mipicsi";
		resets = <&rstc RST_MIPICSI4>;
		reset-names = "rstc_mipicsi";
		sunplus,id = <4>;
#if defined(IMX219_IN4) || defined(TP2815_IN4)
		status = "okay";
#else
		status = "disabled";
#endif

		/* Virtual channel related properties */
		max_channels = <4>;
#ifdef IMX219_IN4
		num_channels = <1>;
#elif defined(TP2815_IN4)
	#ifdef TP2815_IN4_2VC
		num_channels = <2>;
	#else
		num_channels = <1>;
	#endif
#else
		num_channels = <2>;
#endif

		ports {
			#address-cells = <1>;
			#size-cells = <0>;

			/* Input port node, sigle endpoint, connected to the CSI-2 transmitter */
#ifdef IMX219_IN4 /* Add imx219 subnode in i2c2 */
			port@0 {
				reg = <0>;

				/* MIPI CSI-2 bus endpoint */
				csi2_4: endpoint {
					remote-endpoint = <&imx219_4>;
					bus-type = <4>;
					clock-lanes = <0>;
					data-lanes = <1 2>;
				};
			};
#endif
#ifdef TP2815_IN4 /* Add tp2815 subnode in i2c2 */
			port@0 {
				reg = <0>;

				/* MIPI CSI-2 bus endpoint */
				csi2_4: endpoint {
					remote-endpoint = <&tp2815_4>;
					bus-type = <4>;
					clock-lanes = <0>;
	#ifdef TP2815_IN4_1LANE
					data-lanes = <1>;
	#else
					data-lanes = <1 2>;
	#endif
				};
			};
#endif

			/* Output port node, multiple endpoints, connected to VIN modules */
			port@1 {
				#address-cells = <1>;
				#size-cells = <0>;

				reg = <1>;

				csi4vin8: endpoint@0 {
					reg = <0>;
					remote-endpoint = <&vin8csi4>;
				};

				csi4vin9: endpoint@1 {
					reg = <1>;
					remote-endpoint = <&vin9csi4>;
				};
			};
		};
	};

	vin8: video@f8005980 {
		compatible = "sunplus,sp7350-vin";
		reg = <0x0 0xf8005980 0x0 0x80>;
		reg-names = "csiiw";
		interrupt-parent = <&gic>;
		interrupts = <GIC_SPI 44 IRQ_TYPE_LEVEL_HIGH>,
			     <GIC_SPI 45 IRQ_TYPE_LEVEL_HIGH>;
		interrupt-names = "fs_irq", "fe_irq";
		clocks = <&clkc VI4_CSIIW0>;
		clock-names = "clk_csiiw";
		resets = <&rstc RST_VI4_CSIIW0>;
		reset-names = "rstc_csiiw";
		memory-region = <&mipicsirx_reserve>;
		sunplus,id = <8>;
#if defined(IMX219_IN4) || defined(TP2815_IN4)
		status = "okay";
#else
		status = "disabled";
#endif

		ports {
			#address-cells = <1>;
			#size-cells = <0>;

			/* Input port node, default mode, connected to CSI-2 receivers */
			port@1 {
				#address-cells = <1>;
				#size-cells = <0>;

				reg = <1>;

				vin8csi4: endpoint@4 {
					reg = <4>;
					remote-endpoint = <&csi4vin8>;
				};
			};
		};
	};

	vin9: video@f8005a00 {
		compatible = "sunplus,sp7350-vin";
		reg = <0x0 0xf8005a00 0x0 0x80>;
		reg-names = "csiiw";
		interrupt-parent = <&gic>;
		interrupts = <GIC_SPI 46 IRQ_TYPE_LEVEL_HIGH>,
			     <GIC_SPI 47 IRQ_TYPE_LEVEL_HIGH>;
		interrupt-names = "fs_irq", "fe_irq";
		clocks = <&clkc VI4_CSIIW1>;
		clock-names = "clk_csiiw";
		resets = <&rstc RST_VI4_CSIIW1>;
		reset-names = "rstc_csiiw";
		memory-region = <&mipicsirx_reserve>;
		sunplus,id = <9>;
#if defined(TP2815_IN4) && defined(TP2815_IN4_2VC)
		status = "okay";
#else
		status = "disabled";
#endif

		ports {
			#address-cells = <1>;
			#size-cells = <0>;

			/* Input port node, default mode, connected to CSI-2 receivers */
			port@1 {
				#address-cells = <1>;
				#size-cells = <0>;

				reg = <1>;

				vin9csi4: endpoint@4 {
					reg = <4>;
					remote-endpoint = <&csi4vin9>;
				};
			};
		};
	};

	mipicsirx5: csirx@f8005500 {
		compatible = "sunplus,sp7350-mipicsi-rx";
		reg = <0x0 0xf8005500 0x0 0x80>;
		reg-names = "mipicsi";
		clocks = <&clkc MIPICSI5>;
		clock-names = "clk_mipicsi";
		resets = <&rstc RST_MIPICSI5>;
		reset-names = "rstc_mipicsi";
		sunplus,id = <5>;
#if defined(IMX219_IN5) || defined(TP2815_IN5)
		status = "okay";
#else
		status = "disabled";
#endif

		/* Virtual channel related properties */
		max_channels = <4>;
#if defined(IMX219_IN5)
		num_channels = <1>;
#elif defined(TP2815_IN5)
	#ifdef TP2815_IN5_4VC
		num_channels = <4>;
	#elif defined(TP2815_IN5_2VC)
		num_channels = <2>;
	#else
		num_channels = <1>;
	#endif
#else
		num_channels = <4>;
#endif

		ports {
			#address-cells = <1>;
			#size-cells = <0>;

			/* Input port node, sigle endpoint, connected to the CSI-2 transmitter */
#ifdef IMX219_IN5 /* Add imx219 subnode in i2c3 */
			port@0 {
				reg = <0>;

				/* MIPI CSI-2 bus endpoint */
				csi2_5: endpoint {
					remote-endpoint = <&imx219_5>;
					bus-type = <4>;
					clock-lanes = <0>;
					data-lanes = <1 2>;
				};
			};
#endif
#ifdef TP2815_IN5 /* Add tp2815 subnode in i2c3 */
			port@0 {
				reg = <0>;

				/* MIPI CSI-2 bus endpoint */
				csi2_5: endpoint {
					remote-endpoint = <&tp2815_5>;
					bus-type = <4>;
					clock-lanes = <0>;
	#ifdef TP2815_IN5_1LANE
					data-lanes = <1>;
	#elif defined(TP2815_IN5_2LANES)
					data-lanes = <1 2>;
	#else
					data-lanes = <1 2 3 4>;
	#endif
				};
			};
#endif

			/* Output port node, multiple endpoints, connected to VIN modules */
			port@1 {
				#address-cells = <1>;
				#size-cells = <0>;

				reg = <1>;

				csi5vin10: endpoint@0 {
					reg = <0>;
					remote-endpoint = <&vin10csi5>;
				};

				csi5vin11: endpoint@1 {
					reg = <1>;
					remote-endpoint = <&vin11csi5>;
				};

				csi5vin12: endpoint@2 {
					reg = <2>;
					remote-endpoint = <&vin12csi5>;
				};

				csi5vin13: endpoint@3 {
					reg = <3>;
					remote-endpoint = <&vin13csi5>;
				};
			};
		};
	};

	vin10: video@f8005a80 {
		compatible = "sunplus,sp7350-vin";
		reg = <0x0 0xf8005a80 0x0 0x80>;
		reg-names = "csiiw";
		interrupt-parent = <&gic>;
		interrupts = <GIC_SPI 170 IRQ_TYPE_LEVEL_HIGH>,
			     <GIC_SPI 171 IRQ_TYPE_LEVEL_HIGH>;
		interrupt-names = "fs_irq", "fe_irq";
		clocks = <&clkc VI5_CSIIW0>;
		clock-names = "clk_csiiw";
		resets = <&rstc RST_VI5_CSIIW0>;
		reset-names = "rstc_csiiw";
		memory-region = <&mipicsirx_reserve>;
		sunplus,id = <10>;
#if defined(IMX219_IN5) || defined(TP2815_IN5)
		status = "okay";
#else
		status = "disabled";
#endif

		ports {
			#address-cells = <1>;
			#size-cells = <0>;

			/* Input port node, default mode, connected to CSI-2 receivers */
			port@1 {
				#address-cells = <1>;
				#size-cells = <0>;

				reg = <1>;

				vin10csi5: endpoint@5 {
					reg = <5>;
					remote-endpoint = <&csi5vin10>;
				};
			};
		};
	};

	vin11: video@f8005b00 {
		compatible = "sunplus,sp7350-vin";
		reg = <0x0 0xf8005b00 0x0 0x80>;
		reg-names = "csiiw";
		interrupt-parent = <&gic>;
		interrupts = <GIC_SPI 172 IRQ_TYPE_LEVEL_HIGH>,
			     <GIC_SPI 173 IRQ_TYPE_LEVEL_HIGH>;
		interrupt-names = "fs_irq", "fe_irq";
		clocks = <&clkc VI5_CSIIW1>;
		clock-names = "clk_csiiw";
		resets = <&rstc RST_VI5_CSIIW1>;
		reset-names = "rstc_csiiw";
		memory-region = <&mipicsirx_reserve>;
		sunplus,id = <11>;
#if defined(TP2815_IN5) && defined(TP2815_IN5_2VC)
		status = "okay";
#else
		status = "disabled";
#endif

		ports {
			#address-cells = <1>;
			#size-cells = <0>;

			/* Input port node, default mode, connected to CSI-2 receivers */
			port@1 {
				#address-cells = <1>;
				#size-cells = <0>;

				reg = <1>;

				vin11csi5: endpoint@5 {
					reg = <5>;
					remote-endpoint = <&csi5vin11>;
				};
			};
		};
	};

	vin12: video@f8005b80 {
		compatible = "sunplus,sp7350-vin";
		reg = <0x0 0xf8005b80 0x0 0x80>;
		reg-names = "csiiw";
		interrupt-parent = <&gic>;
		interrupts = <GIC_SPI 174 IRQ_TYPE_LEVEL_HIGH>,
			     <GIC_SPI 175 IRQ_TYPE_LEVEL_HIGH>;
		interrupt-names = "fs_irq", "fe_irq";
		clocks = <&clkc VI5_CSIIW2>;
		clock-names = "clk_csiiw";
		resets = <&rstc RST_VI5_CSIIW2>;
		reset-names = "rstc_csiiw";
		memory-region = <&mipicsirx_reserve>;
		sunplus,id = <12>;
		status = "disabled";

		ports {
			#address-cells = <1>;
			#size-cells = <0>;

			/* Input port node, default mode, connected to CSI-2 receivers */
			port@1 {
				#address-cells = <1>;
				#size-cells = <0>;

				reg = <1>;

				vin12csi5: endpoint@5 {
					reg = <5>;
					remote-endpoint = <&csi5vin12>;
				};
			};
		};
	};

	vin13: video@f8005c00 {
		compatible = "sunplus,sp7350-vin";
		reg = <0x0 0xf8005c00 0x0 0x80>;
		reg-names = "csiiw";
		interrupt-parent = <&gic>;
		interrupts = <GIC_SPI 176 IRQ_TYPE_LEVEL_HIGH>,
			     <GIC_SPI 177 IRQ_TYPE_LEVEL_HIGH>;
		interrupt-names = "fs_irq", "fe_irq";
		clocks = <&clkc VI5_CSIIW3>;
		clock-names = "clk_csiiw";
		resets = <&rstc RST_VI5_CSIIW3>;
		reset-names = "rstc_csiiw";
		memory-region = <&mipicsirx_reserve>;
		sunplus,id = <13>;
		status = "disabled";

		ports {
			#address-cells = <1>;
			#size-cells = <0>;

			/* Input port node, default mode, connected to CSI-2 receivers */
			port@1 {
				#address-cells = <1>;
				#size-cells = <0>;

				reg = <1>;

				vin13csi5: endpoint@5 {
					reg = <5>;
					remote-endpoint = <&csi5vin13>;
				};
			};
		};
	};

	video_codec {
		compatible = "sunplus,sp7350-hantro-codec";
		clocks = <&clkc VIDEO_CODEC>;
		clock-names = "clk_vcodec";
		resets = <&rstc RST_VIDEO_CODEC>;
		reset-names = "rstc_vcodec";
	};

	video_codec_dec: hantro_vc8000d@f8168000 {
		compatible = "sunplus,sp7350-hantro-vc8000d";
		reg = <0x00 0xf8168000 0x00 0x1d8>;
		interrupt-parent = <&gic>;
		interrupts = <GIC_SPI 167 IRQ_TYPE_LEVEL_HIGH>;
		clocks = <&clkc VCD>;
		clock-names = "clk_vc8000d";
		resets = <&rstc RST_VCD>;
		reset-names = "rstc_vc8000d";
	};

	video_codec_enc: hantro_vc8000e@f80ff000 {
		compatible = "sunplus,sp7350-hantro-vc8000e";
		reg = <0x00 0xf80ff000 0x00 0xfff>;
		interrupt-parent = <&gic>;
		interrupts = <GIC_SPI 77 IRQ_TYPE_LEVEL_HIGH>;
		clocks = <&clkc VCE>;
		clock-names = "clk_vc8000e";
		resets = <&rstc RST_VCE>;
		reset-names = "rstc_vc8000e";
	};

	video_codec_emem {
		compatible = "sunplus,sp7350-hantro-emem";
		memory-region = <&video_codec_encode>;
		video_codec-supply = <&video_codec_core_0v8>;
	};

	video_codec_dmem {
		compatible = "sunplus,sp7350-hantro-dmem";
		memory-region = <&video_codec_decode>;
		video_codec-supply = <&video_codec_core_0v8>;
	};

	galcore: galcore@f8140000 {
		compatible = "galcore";
		reg = <0x0 0xf8140000 0x0 0x20000>;
		dev_name = "galcore";
		memory-region = <&npu_reserve>;
		interrupt-parent = <&gic>;
		interrupts = <GIC_SPI 165 IRQ_TYPE_LEVEL_HIGH>;
		npu_core-supply = <&npu_core_0v8>;
		clocks = <&clkc NPU>;
		clock-names = "clk_vip9000";
		clock-frequency = <900000000>;
		resets = <&rstc RST_NPU>;
		reset-names = "rstc_vip9000";
		status = "okay";
	};

	poweroff {
		compatible = "sunplus,sp-poweroff";
	};

	fb_disp_device {
		compatible = "sunplus,sp7350-fb";
		memory-region = <&fb_disp_reserve>;
		status = "okay";
	};

	display: display@f8005c80 {
		compatible = "sunplus,sp7350-display";
		reg = <0x00 0xf8005c80 0x00 0xa80>, <0x00 0xf8800180 0x00 0x80>;
		interrupt-parent = <&gic>;
		interrupts =
			<GIC_SPI 104 IRQ_TYPE_LEVEL_HIGH>, <GIC_SPI 105 IRQ_TYPE_LEVEL_HIGH>,
			<GIC_SPI 106 IRQ_TYPE_LEVEL_HIGH>, <GIC_SPI 107 IRQ_TYPE_LEVEL_HIGH>;
		clocks =
			<&clkc DISPSYS>, <&clkc DMIX>, <&clkc GPOST0>, <&clkc GPOST1>,
			<&clkc GPOST2>, <&clkc GPOST3>, <&clkc IMGREAD0>, <&clkc MIPITX>,
			<&clkc OSD0>, <&clkc OSD1>, <&clkc OSD2>, <&clkc OSD3>,
			<&clkc TCON>, <&clkc TGEN>, <&clkc VPOST0>, <&clkc VSCL0>;
		clock-names =
			"clkc_dispsys", "clkc_dmix", "clkc_gpost0", "clkc_gpost1",
			"clkc_gpost2", "clkc_gpost3", "clkc_imgread0", "clkc_mipitx",
			"clkc_osd0", "clkc_osd1", "clkc_osd2", "clkc_osd3",
			"clkc_tcon", "clkc_tgen", "clkc_vpost0", "clkc_vscl0";
		resets =
			<&rstc RST_DISPSYS>, <&rstc RST_DMIX>, <&rstc RST_GPOST0>, <&rstc RST_GPOST1>,
			<&rstc RST_GPOST2>, <&rstc RST_GPOST3>, <&rstc RST_IMGREAD0>, <&rstc RST_MIPITX>,
			<&rstc RST_OSD0>, <&rstc RST_OSD1>, <&rstc RST_OSD2>, <&rstc RST_OSD3>,
			<&rstc RST_TCON>, <&rstc RST_TGEN>, <&rstc RST_VPOST0>, <&rstc RST_VSCL0>;
		reset-names =
			"rstc_dispsys", "rstc_dmix", "rstc_gpost0", "rstc_gpost1",
			"rstc_gpost2", "rstc_gpost3", "rstc_imgread0", "rstc_mipitx",
			"rstc_osd0", "rstc_osd1", "rstc_osd2", "rstc_osd3",
			"rstc_tcon", "rstc_tgen", "rstc_vpost0", "rstc_vscl0";
		status = "okay";
#if defined(DISP_MIPITX_CSI)
	#if defined(DISP_MIPITX_CSI_480P)
		sp7350,dev_name = "MIPITX-CSI-TEST_480P";
		sp7350,osd0_layer = <0 0 720 480 0x4>; /* 0x4 = YUY2 */
		sp7350,vpp0_layer = <0 0 720 480 720 480 0x2>; /* 0x2 = YUY2 */
		sp7350,disp_output = <720 480 0x1>; /* 0x1:MIPITX CSI */
	#elif defined(DISP_MIPITX_CSI_720P)
		sp7350,dev_name = "MIPITX-CSI-TEST_720P";
		sp7350,osd0_layer = <0 0 1280 720 0x4>; /* 0x4 = YUY2 */
		sp7350,vpp0_layer = <0 0 1280 720 1280 720 0x2>; /* 0x2 = YUY2 */
		sp7350,disp_output = <1280 720 0x1>; /* 0x1:MIPITX CSI */
	#elif defined(DISP_MIPITX_CSI_1080P)
		sp7350,dev_name = "MIPITX-CSI-TEST_1080P";
		sp7350,osd0_layer = <0 0 1920 1080 0x4>; /* 0x4 = YUY2 */
		sp7350,vpp0_layer = <0 0 1920 1080 1920 1080 0x2>; /* 0x2 = YUY2 */
		sp7350,disp_output = <1920 1080 0x1>; /* 0x1:MIPITX CSI */
	#elif defined(DISP_MIPITX_CSI_3840)
		sp7350,dev_name = "MIPITX-CSI-TEST_3840";
		sp7350,osd0_layer = <0 0 3840 2880 0x4>; /* 0x4 = YUY2 */
		sp7350,vpp0_layer = <0 0 3840 2880 3840 2880 0x2>; /* 0x2 = YUY2 */
		sp7350,disp_output = <3840 2880 0x1>; /* 0x1:MIPITX CSI */
	#else
		sp7350,dev_name = "MIPITX-CSI-TEST_720P";
		sp7350,osd0_layer = <0 0 1280 720 0x4>; /* 0x4 = YUY2 */
		sp7350,vpp0_layer = <0 0 1280 720 1280 720 0x2>; /* 0x2 = YUY2 */
		sp7350,disp_output = <1280 720 0x1>; /* 0x1:MIPITX CSI */
	#endif
		sp7350,disp_mipitx_lane = <0x4>; /* 0x0:MIPITX lane */
		sp7350,disp_mipitx_clk_edge = <0x0>; /* 0x0:Raising Edge */
		sp7350,disp_mipitx_sync_timing = <0x1>; /* 0x1:Sync Event */
		sp7350,disp_mipitx_format = <0x1>; /* 0x1:MIPITX format CSI_16BITS YUY2 */

#elif defined(DISP_MIPITX_DSI_PANEL_240X320)
		sp7350,dev_name = "TCXD024IBLON-2";

		sp7350,osd0_layer = <0 0 240 320 0xe>; /* 0xe = ARGB8888 */
		//sp7350,osd1_layer = <0 0 240 320 0xe>; /* 0xe = ARGB8888 */
		//sp7350,osd2_layer = <0 0 240 320 0xe>; /* 0xe = ARGB8888 */
		//sp7350,osd3_layer = <0 0 240 320 0xe>; /* 0xe = ARGB8888 */
		sp7350,vpp0_layer = <0 0 720 480 720 480 0x2>; /* 0x2 = YUY2 */

		sp7350,disp_output = <240 320 0x0>; /* 0x0:MIPITX DSI */
		sp7350,disp_mipitx_lane = <0x1>; /* 0x0:MIPITX lane */
		sp7350,disp_mipitx_clk_edge = <0x1>; /* 0x1:Falling Edge */
		sp7350,disp_mipitx_sync_timing = <0x0>; /* 0x1:Sync Pulse */
		sp7350,disp_mipitx_format = <0x3>; /* 0x3:MIPITX DSI RGB888 */
#elif defined(DISP_MIPITX_DSI_PANEL_480X1280)
		//reset-gpios = <&pctl 56 GPIO_ACTIVE_HIGH>;
		sp7350,dev_name = "HXM0686TFT-001";
		sp7350,osd0_layer = <0 0 480 1280 0xe>; /* 0xe = ARGB8888 */
		sp7350,osd1_layer = <0 240 480 1280 0x2>; /* 0x2 = 8bpp */
		sp7350,osd2_layer = <0 480 480 1280 0x2>; /* 0x2 = 8bpp */
		sp7350,osd3_layer = <0 720 480 1280 0x2>; /* 0x2 = 8bpp */

		//sp7350,osd0_layer = <0 0 200 200 0xe>; /* 0xe = ARGB8888 */
		//sp7350,osd1_layer = <280 0 200 200 0xe>; /* 0xe = ARGB8888 */
		//sp7350,osd2_layer = <0 1080 200 200 0xe>; /* 0xe = ARGB8888 */
		//sp7350,osd3_layer = <280 1080 200 200 0xe>; /* 0xe = ARGB8888 */
			/* 0x2 = 8bpp (ARGB)
			 * 0x4 = YUY2
			 * 0x8 = RGB565
			 * 0x9 = ARGB1555
			 * 0xa = RGBA4444
			 * 0xb = ARGB4444
			 * 0xd = RGBA8888
			 * 0xe = ARGB8888
			 */
	#if defined(DISP_MIPITX_DSI_VPP_SRC_480P)
		sp7350,vpp0_layer = <0 0 720 480 720 480 0x2>; /* 0x2 = YUY2 */
	#elif defined(DISP_MIPITX_DSI_VPP_SRC_720P)
		sp7350,vpp0_layer = <0 0 1280 720 1280 720 0x2>; /* 0x2 = YUY2 */
	#elif defined(DISP_MIPITX_DSI_VPP_SRC_1080P)
		sp7350,vpp0_layer = <0 0 1920 1080 1920 1080 0x2>; /* 0x2 = YUY2 */
	#elif defined(DISP_MIPITX_DSI_VPP_SRC_3840)
		sp7350,vpp0_layer = <0 0 3840 2880 3840 2880 0x2>; /* 0x2 = YUY2 */
	#else
		sp7350,vpp0_layer = <0 0 720 480 720 480 0x2>; /* 0x2 = YUY2 */
			/* 0x1 = UYVY
			 * 0x2 = YUY2
			 * 0x3 = NV16
			 * 0x6 = NV24
			 * 0x7 = NV12
			 * else YUY2
			 */
	#endif

		sp7350,disp_output = <480 1280 0x0>; /* 0x0:MIPITX DSI */
			/* 0x0:MIPITX DSI
			 * 0x1:MIPITX CSI
			 */
		sp7350,disp_mipitx_lane = <0x4>; /* 0x0:MIPITX lane */
			/* 0x1 = 1 lane
			 * 0x2 = 2 lane
			 * 0x4 = 4 lane
			 */
		sp7350,disp_mipitx_clk_edge = <0x1>; /* 0x1:Falling Edge */
			/* 0x0:Raising Edge
			 * 0x1:Falling Edge
			 */
		sp7350,disp_mipitx_sync_timing = <0x1>; /* 0x1:Sync Event */
			/* 0x0:Sync Pulse
			 * 0x1:Sync Event
			 */
		sp7350,disp_mipitx_format = <0x3>; /* 0x3:MIPITX DSI RGB888 */
			/* 0x0 = DSI RGB565        / CSI_16BITS RGB565
			 * 0x1 = DSI RGB666_18BITS / CSI_16BITS YUY2 8bit
			 * 0x2 = DSI RGB666_24BITS / CSI_20BITS YUY2 10bit
			 * 0x3 = DSI RGB888        / CSI_24BITS RGB888
			 */
#elif defined(LT8912B_HDMI_ENABLE) /* Add lt8912b subnode */
		sp7350,dev_name = "LT8912B-HDMI";
	#if defined(LT8912B_HDMI_480P)
		sp7350,osd0_layer = <0 0 720 480 0x8>; /* 0x8 = RGB565 */
		sp7350,osd1_layer = <0 0 720 480 0x8>; /* 0x8 = RGB565 */
		sp7350,osd2_layer = <0 0 720 480 0x8>; /* 0x8 = RGB565 */
		sp7350,osd3_layer = <0 0 720 480 0x8>; /* 0x8 = RGB565 */
		sp7350,vpp0_layer = <0 0 720 480 720 480 0x2>; /* 0x2 = YUY2 */
		sp7350,disp_output = <720 480 0x0>; /* 0x0:MIPITX DSI */
	#elif defined(LT8912B_HDMI_720P)
		sp7350,osd0_layer = <0 0 1280 720 0x8>; /* 0x8 = RGB565 */
		sp7350,osd1_layer = <0 0 1280 720 0x8>; /* 0x8 = RGB565 */
		sp7350,osd2_layer = <0 0 1280 720 0x8>; /* 0x8 = RGB565 */
		sp7350,osd3_layer = <0 0 1280 720 0x8>; /* 0x8 = RGB565 */
		sp7350,vpp0_layer = <0 0 1280 720 1280 720 0x2>; /* 0x2 = YUY2 */
		sp7350,disp_output = <1280 720 0x0>; /* 0x0:MIPITX DSI */
	#elif defined(LT8912B_HDMI_1080P)
		sp7350,osd0_layer = <0 0 1920 1080 0x8>; /* 0x8 = RGB565 */
		sp7350,osd1_layer = <0 0 1920 1080 0x8>; /* 0x8 = RGB565 */
		sp7350,osd2_layer = <0 0 1920 1080 0x8>; /* 0x8 = RGB565 */
		sp7350,osd3_layer = <0 0 1920 1080 0x8>; /* 0x8 = RGB565 */
		sp7350,vpp0_layer = <0 0 1920 1080 1920 1080 0x2>; /* 0x2 = YUY2 */
		sp7350,disp_output = <1920 1080 0x0>; /* 0x0:MIPITX DSI */
	#else
		sp7350,osd0_layer = <0 0 1280 720 0x8>; /* 0x8 = RGB565 */
		sp7350,osd1_layer = <0 0 1280 720 0x8>; /* 0x8 = RGB565 */
		sp7350,osd2_layer = <0 0 1280 720 0x8>; /* 0x8 = RGB565 */
		sp7350,osd3_layer = <0 0 1280 720 0x8>; /* 0x8 = RGB565 */
		sp7350,vpp0_layer = <0 0 1280 720 1280 720 0x2>; /* 0x2 = YUY2 */
		sp7350,disp_output = <1280 720 0x0>; /* 0x0:MIPITX DSI */
	#endif
		sp7350,disp_mipitx_lane = <0x4>; /* 0x0:MIPITX lane */
		sp7350,disp_mipitx_clk_edge = <0x0>; /* 0x1:Raising Edge */
		sp7350,disp_mipitx_sync_timing = <0x1>; /* 0x1:Sync Event */
		sp7350,disp_mipitx_format = <0x3>; /* 0x3:MIPITX DSI RGB888 */
#endif
#ifdef LT8912B_HDMI_ENABLE /* Add lt8912b subnode */
		port {
			disp_phy: endpoint {
				remote-endpoint = <&lt8912b_in>;
			};
		};
#endif
	};

#ifdef LT8912B_HDMI_ENABLE /* Add lt8912b subnode */
	hdmi-connector {
		compatible = "hdmi-connector";
		label = "hdmi";
		type = "a";

		port {
			hdmi_con_out: endpoint {
				remote-endpoint = <&lt8912b_out>;
			};
		};
	};
#endif

#if 0
	dummymaster: dm@f8000700 {
		compatible = "sunplus,sp7350-dm-test";
		reg = <0x0 0xf8800100 0x0 0x80>, <0x0 0xf8000700 0x0 0x80>,
			<0x0 0xf800a880 0x0 0x80>; /* G14 G337 */
		clocks = <&clkc DUMMY_MASTER0>, <&clkc DUMMY_MASTER1>;
		resets = <&rstc DUMMY_MASTER0>, <&rstc DUMMY_MASTER1>;
	};
#endif

	watchdog: watchdog@f800061c {
		compatible = "sunplus,sp7350-wdt";
		reg = <0x00 0xf800061c 0x00 0x08>, <0x00 0xf800066c 0x00 0x08>,
			<0x00 0xf8800258 0x00 0x04>, <0x00 0xf800060c 0x00 0x04>;
		interrupt-parent = <&gic>;
		interrupts = <GIC_SPI 113 IRQ_TYPE_LEVEL_HIGH>;
		clocks = <&clkc STC_AV3>;
		resets = <&rstc RST_STC_AV3>;
		timeout-sec = <10>;
	};

	timer_test: timer_test@f8000580 {
		compatible = "sunplus,sp7350-timer-test";
		reg =
			<0x00 0xf8000580 0x00 0x80>, <0x00 0xf8000600 0x00 0x80>,
			<0x00 0xf8800b80 0x00 0x80>, <0x00 0xf8800c00 0x00 0x80>,
			<0x00 0xf8800c80 0x00 0x80>, <0x00 0xf8800d00 0x00 0x80>,
			<0x00 0xf8801300 0x00 0x80>;
		reg-names =
			"stc_timestamp", "stc_av3",
			"stc", "stc_av0",
			"stc_av1", "stc_av2",
			"stc_av4";
		interrupt-parent = <&gic>;
		interrupts =
			<GIC_SPI 52 IRQ_TYPE_EDGE_RISING>,/* STC_TIMESTAMP_INTERRUPT_TIMER0 */
			<GIC_SPI 53 IRQ_TYPE_EDGE_RISING>,/* STC_TIMESTAMP_INTERRUPT_TIMER1 */
			<GIC_SPI 54 IRQ_TYPE_EDGE_RISING>,/* STC_TIMESTAMP_INTERRUPT_TIMER2B */
			<GIC_SPI 55 IRQ_TYPE_EDGE_RISING>,/* STC_TIMESTAMP_INTERRUPT_TIMER3B */
			<GIC_SPI 114 IRQ_TYPE_EDGE_RISING>,/* STC_AV3_INTERRUPT_TIMER0 */
			<GIC_SPI 115 IRQ_TYPE_EDGE_RISING>,/* STC_AV3_INTERRUPT_TIMER1 */
			<GIC_SPI 116 IRQ_TYPE_EDGE_RISING>,/* STC_AV3_INTERRUPT_TIMER2B */
			<GIC_SPI 117 IRQ_TYPE_EDGE_RISING>,/* STC_AV3_INTERRUPT_TIMER3B */
			<GIC_SPI 129 IRQ_TYPE_EDGE_RISING>,/* STC_INTERRUPT_TIMER0 */
			<GIC_SPI 130 IRQ_TYPE_EDGE_RISING>,/* STC_INTERRUPT_TIMER1 */
			<GIC_SPI 131 IRQ_TYPE_EDGE_RISING>,/* STC_INTERRUPT_TIMER2B */
			<GIC_SPI 132 IRQ_TYPE_EDGE_RISING>,/* STC_INTERRUPT_TIMER3B */
			<GIC_SPI 133 IRQ_TYPE_EDGE_RISING>,/* STC_AV0_INTERRUPT_TIMER0 */
			<GIC_SPI 134 IRQ_TYPE_EDGE_RISING>,/* STC_AV0_INTERRUPT_TIMER1 */
			<GIC_SPI 135 IRQ_TYPE_EDGE_RISING>,/* STC_AV0_INTERRUPT_TIMER2B */
			<GIC_SPI 136 IRQ_TYPE_EDGE_RISING>,/* STC_AV0_INTERRUPT_TIMER3B */
			<GIC_SPI 137 IRQ_TYPE_EDGE_RISING>,/* STC_AV1_INTERRUPT_TIMER0 */
			<GIC_SPI 138 IRQ_TYPE_EDGE_RISING>,/* STC_AV1_INTERRUPT_TIMER1 */
			<GIC_SPI 139 IRQ_TYPE_EDGE_RISING>,/* STC_AV1_INTERRUPT_TIMER2B */
			<GIC_SPI 140 IRQ_TYPE_EDGE_RISING>,/* STC_AV1_INTERRUPT_TIMER3B */
			<GIC_SPI 142 IRQ_TYPE_EDGE_RISING>,/* STC_AV2_INTERRUPT_TIMER0 */
			<GIC_SPI 143 IRQ_TYPE_EDGE_RISING>,/* STC_AV2_INTERRUPT_TIMER1 */
			<GIC_SPI 144 IRQ_TYPE_EDGE_RISING>,/* STC_AV2_INTERRUPT_TIMER2B */
			<GIC_SPI 145 IRQ_TYPE_EDGE_RISING>,/* STC_AV2_INTERRUPT_TIMER3B */
			<GIC_SPI 186 IRQ_TYPE_EDGE_RISING>,/* STC_AV4_INTERRUPT_TIMER0 */
			<GIC_SPI 187 IRQ_TYPE_EDGE_RISING>,/* STC_AV4_INTERRUPT_TIMER1 */
			<GIC_SPI 188 IRQ_TYPE_EDGE_RISING>,/* STC_AV4_INTERRUPT_TIMER2B */
			<GIC_SPI 189 IRQ_TYPE_EDGE_RISING>;/* STC_AV4_INTERRUPT_TIMER3B */
	};

	ipc_test: ipc_test@f8008100 {
		compatible = "sunplus,sp7350-ipc-test";
		reg = <0x0 0xf8008100 0x0 0x7C>, <0x0 0xf8008180 0x0 0x7C>; /* G258 ~ G259 */
		reg-names = "cpu0_to_cpu2", "cpu2_to_cpu0";
		interrupt-parent = <&gic>;
		interrupts =
			<GIC_SPI 9 IRQ_TYPE_EDGE_RISING>, /* MAILBOX_to_CM4 CPU2_DIRECT_INT0 */
			<GIC_SPI 10 IRQ_TYPE_EDGE_RISING>, /* MAILBOX_to_CM4 CPU2_DIRECT_INT1 */
			<GIC_SPI 13 IRQ_TYPE_EDGE_RISING>, /* MAILBOX_to_CM4 CPU2_DIRECT_INT2 */
			<GIC_SPI 14 IRQ_TYPE_EDGE_RISING>, /* MAILBOX_to_CM4 CPU2_DIRECT_INT3 */
			<GIC_SPI 25 IRQ_TYPE_EDGE_RISING>, /* MAILBOX_to_CM4 CPU2_DIRECT_INT4 */
			<GIC_SPI 26 IRQ_TYPE_EDGE_RISING>, /* MAILBOX_to_CM4 CPU2_DIRECT_INT5 */
			<GIC_SPI 78 IRQ_TYPE_EDGE_RISING>, /* MAILBOX_to_CM4 CPU2_DIRECT_INT6 */
			/*<GIC_SPI 79 IRQ_TYPE_EDGE_RISING>, /* MAILBOX_to_CM4 CPU2_DIRECT_INT7 */
			<GIC_SPI 118 IRQ_TYPE_EDGE_RISING>, /* MAILBOX_to_CA55 CPU0_DIRECT_INT0 */
			<GIC_SPI 119 IRQ_TYPE_EDGE_RISING>, /* MAILBOX_to_CA55 CPU0_DIRECT_INT1 */
			<GIC_SPI 120 IRQ_TYPE_EDGE_RISING>, /* MAILBOX_to_CA55 CPU0_DIRECT_INT2 */
			<GIC_SPI 121 IRQ_TYPE_EDGE_RISING>, /* MAILBOX_to_CA55 CPU0_DIRECT_INT3 */
			<GIC_SPI 122 IRQ_TYPE_EDGE_RISING>, /* MAILBOX_to_CA55 CPU0_DIRECT_INT4 */
			<GIC_SPI 123 IRQ_TYPE_EDGE_RISING>, /* MAILBOX_to_CA55 CPU0_DIRECT_INT5 */
			<GIC_SPI 124 IRQ_TYPE_EDGE_RISING>, /* MAILBOX_to_CA55 CPU0_DIRECT_INT6 */
			/*<GIC_SPI 125 IRQ_TYPE_EDGE_RISING>, /* MAILBOX_to_CA55 CPU0_DIRECT_INT7 */
			<GIC_SPI 126 IRQ_TYPE_EDGE_RISING>, /* MAILBOX_to_CA55 CPU0_INT */
			<GIC_SPI 127 IRQ_TYPE_EDGE_RISING>; /* MAILBOX_to_CM4 CPU1_INT */
	};

	pctl: pinctrl@f8800080 {
		compatible = "sunplus,sp7350-pctl";
		reg = <0x0 0xf8800080 0x0 0x2c>,
		      <0x0 0xf88032e4 0x0 0x1c>,
		      <0x0 0xf8803380 0x0 0x180>,
		      <0x0 0xf8802f80 0x0 0x1c>;
		reg-names = "moon1", "first", "gpioxt", "gpio_ao_int";
		gpio-controller;
		#gpio-cells = <2>;

		sunplus,ao-pin-prescale = <2500>;
		sunplus,ao-pin-debounce = <10>;

		emmc_pins: pinmux_emmc-pins {
			function = "EMMC";
			groups = "EMMC";
		};

		sdcard_pins: pinmux_sdcard-pins {
			function = "SD_CARD";
			groups = "SD_CARD";
		};

		typec_pins: pinmux_typec-pins {
			sunplus,pins = < SPPCTL_IOPAD(98, SPPCTL_PCTL_G_GPIO, 0, 0) >;
		};

		dwc3id_pins: pinmux_usb3id-pins {
			sunplus,pins = < SPPCTL_IOPAD(99, SPPCTL_PCTL_G_GPIO, 0, 0) >;
		};

		spi_nor_pins: pinmux_spi_nor-pins {
			function = "SPI_FLASH";
			groups = "SPI_FLASH";
		};

		spi_nand_pins: pinmux_spi_nand-pins {
			function = "SPI_NAND";
			groups = "SPI_NAND_X1";
		};

		para_nand_pins: pinmux_para_nand-pins {
			function = "PARA_NAND";
			groups = "PARA_NAND";
		};

		uart0_pins: pinmux_uart0-pins {
			function = "UART0";
			groups = "UART0_X1";
		};

		uart1_pins: pinmux_uart1-pins {
			function = "UART1";
			groups = "UART1_X1";
		};
		uart1_fc_pins: pinmux_uart1_fc-pins {
			function = "UART1_FC";
			groups = "UART1_FC_X1";
		};

		uart2_pins: pinmux_uart2-pins {
			function = "UART2";
			groups = "UART2_X1";
		};
		uart2_fc_pins: pinmux_uart2_fc-pins {
			function = "UART2_FC";
			groups = "UART2_FC_X1";
		};

		uart3_pins: pinmux_uart3-pins {
			function = "UART3";
			groups = "UART3_X1";
		};

		uadbg_pins: pinmux_uadbg-pins {
			function = "UADBG";
			groups = "UADBG";
		};

		uart6_pins: pinmux_uart6-pins {
			function = "UART6";
			groups = "UART6_X1";
		};

		uart7_pins: pinmux_uart7-pins {
			function = "UART7";
			groups = "UART7";
		};

		spi_master0_pins: pinmux_spi_master0-pins {
			function = "SPI_MASTER0";
			groups = "SPI_MASTER0_X1";
		};
		spi_master1_pins: pinmux_spi_master1-pins {
			function = "SPI_MASTER1";
			groups = "SPI_MASTER1_X1";
		};
		spi_master2_pins: pinmux_spi_master2-pins {
			function = "SPI_MASTER2";
			groups = "SPI_MASTER2";
		};
		spi_master3_pins: pinmux_spi_master3-pins {
			function = "SPI_MASTER3";
			groups = "SPI_MASTER3_X2";
		};
		spi_master4_pins: pinmux_spi_master4-pins {
			function = "SPI_MASTER4";
			groups = "SPI_MASTER4";
		};
		spi_slave0_pins: pinmux_spi_slave0-pins {
			function = "SPI_SLAVE0";
			groups = "SPI_SLAVE0_X1";
		};

		i2c_combo0_pins: pinmux_i2c_combo0-pins {
			function = "I2C_COMBO0";
			groups = "I2C_COMBO0_X1";
		};
		i2c_combo1_pins: pinmux_i2c_combo1-pins {
			function = "I2C_COMBO1";
			groups = "I2C_COMBO1";
		};
		i2c_combo2_pins: pinmux_i2c_combo2-pins {
			function = "I2C_COMBO2";
			groups = "I2C_COMBO2_X1";
		};
		i2c_combo3_pins: pinmux_i2c_combo3-pins {
			function = "I2C_COMBO3";
			groups = "I2C_COMBO3";
		};
		i2c_combo4_pins: pinmux_i2c_combo4-pins {
			function = "I2C_COMBO4";
			groups = "I2C_COMBO4";
		};
		i2c_combo5_pins: pinmux_i2c_combo5-pins {
			function = "I2C_COMBO5";
			groups = "I2C_COMBO5";
		};
		i2c_combo6_pins: pinmux_i2c_combo6-pins {
			function = "I2C_COMBO6";
			groups = "I2C_COMBO6_X1";
		};
		i2c_combo7_pins: pinmux_i2c_combo7-pins {
			function = "I2C_COMBO7";
			groups = "I2C_COMBO7_X1";
		};
		i2c_combo8_pins: pinmux_i2c_combo8-pins {
			function = "I2C_COMBO8";
			groups = "I2C_COMBO8_X1";
		};
		i2c_combo9_pins: pinmux_i2c_combo9-pins {
			function = "I2C_COMBO9";
			groups = "I2C_COMBO9_X1";
		};

		gmac_pins: pinmux_gmac-pins {
			function = "GMAC";
			groups = "GMAC_RGMII";
		};

		otg_pins: pinmux_otg_pins {
			function = "USB_OTG";
			groups = "USB_OTG";
		};

		sdio_pins: pinmux_sdio-pins {
			function = "SDIO";
			groups = "SDIO";
		};

		pwm0_pins: pinmux_pwm0-pins {
			function = "PWM0";
			groups = "PWM0_X1";
		};

		pwm1_pins: pinmux_pwm1-pins {
			function = "PWM1";
			groups = "PWM1_X1";
		};

		pwm2_pins: pinmux_pwm2-pins {
			function = "PWM2";
			groups = "PWM2_X1";
		};

		pwm3_pins: pinmux_pwm3-pins {
			function = "PWM3";
			groups = "PWM3_X1";
		};

		aud_tdmtx_xck_pins: pinmux_aud_tdmtx_xck-pins {
			function = "AUD_TDMTX_XCK";
			groups = "AUD_TDMTX_XCK";
		};
		aud_dac_xck_pins: pinmux_aud_dac_xck-pins {
			function = "AUD_DAC_XCK";
			groups = "AUD_DAC_XCK";
		};
		aud_dac_xck1_pins: pinmux_aud_dac_xck1-pins {
			function = "AUD_DAC_XCK1";
			groups = "AUD_DAC_XCK1";
		};
		aud_au2_data0_pins: pinmux_aud_au2_data0-pins {
			function = "AUD_AU2_DATA0";
			groups = "AUD_AU2_DATA0";
		};
		aud_au1_data0_pins: pinmux_aud_au1_data0-pins {
			function = "AUD_AU1_DATA0";
			groups = "AUD_AU1_DATA0";
		};
		aud_au2_ck_pins: pinmux_aud_au2_ck-pins {
			function = "AUD_AU2_CK";
			groups = "AUD_AU2_CK";
		};
		aud_au1_ck_pins: pinmux_aud_au1_ck-pins {
			function = "AUD_AU1_CK";
			groups = "AUD_AU1_CK";
		};
		aud_au_adc_data0_pins: pinmux_aud_au_adc_data0-pins {
			function = "AUD_AU_ADC_DATA0";
			groups = "AUD_AU_ADC_DATA0_X1";
		};
		aud_adc2_data0_pins: pinmux_aud_adc2_data0-pins {
			function = "AUD_ADC2_DATA0";
			groups = "AUD_ADC2_DATA0";
		};
		aud_adc1_data0_pins: pinmux_aud_adc1_data0-pins {
			function = "AUD_ADC1_DATA0";
			groups = "AUD_ADC1_DATA0";
		};
		aud_tdm_pins: pinmux_aud_tdm-pins {
			function = "AUD_TDM";
			groups = "AUD_TDM";
		};
		spdif_in_pins: pinmux_spdif_in-pins {
			function = "SPDIF_IN";
			groups = "SPDIF_IN_X1";
		};
		spdif_out_pins: pinmux_spdif_out-pins {
			function = "SPDIF_OUT";
			groups = "SPDIF_OUT_X1";
		};

		gpio_int0_pins: pinmux_gpio_int0-pins {
			function = "INT0";
			groups = "INT0_X1";
		};
		gpio_int1_pins: pinmux_gpio_int1-pins {
			function = "INT1";
			groups = "INT1_X1";
		};
		gpio_int2_pins: pinmux_gpio_int2-pins {
			function = "INT2";
			groups = "INT2_X1";
		};
		gpio_int3_pins: pinmux_gpio_int3-pins {
			function = "INT3";
			groups = "INT3_X1";
		};
		gpio_int4_pins: pinmux_gpio_int4-pins {
			function = "INT4";
			groups = "INT4_X1";
		};
		gpio_int5_pins: pinmux_gpio_int5-pins {
			function = "INT5";
			groups = "INT5_X1";
		};
		gpio_int6_pins: pinmux_gpio_int6-pins {
			function = "INT6";
			groups = "INT6_X1";
		};
		gpio_int7_pins: pinmux_gpio_int7-pins {
			function = "INT7";
			groups = "INT7_X1";
		};

		gpio_ao_int0_pins: pinmux_gpio_ao_int0-pins {
			function = "GPIO_AO_INT0";
			groups = "GPIO_AO_INT0_X1";
			sunplus,ao-pins = <
				SPPCTL_AOIOPAD(0, SPPCTL_AOPIN_OUT0)
				SPPCTL_AOIOPAD(1, SPPCTL_AOPIN_OUT1)
			>;
		};
		gpio_ao_int1_pins: pinmux_gpio_ao_int1-pins {
			function = "GPIO_AO_INT1";
			groups = "GPIO_AO_INT1_X1";
			sunplus,ao-pins = <
				SPPCTL_AOIOPAD(8, 0)
				SPPCTL_AOIOPAD(15, SPPCTL_AOPIN_DEB)
			>;
		};
		gpio_ao_int2_pins: pinmux_gpio_ao_int2-pins {
			function = "GPIO_AO_INT2";
			groups = "GPIO_AO_INT2_X1";
			sunplus,ao-pins = < SPPCTL_AOIOPAD(16, 0) >;
		};
		gpio_ao_int3_pins: pinmux_gpio_ao_int3-pins {
			function = "GPIO_AO_INT3";
			groups = "GPIO_AO_INT3_X1";
			sunplus,ao-pins = < SPPCTL_AOIOPAD(31, 0) >;
		};
	};
};
